[part 1 of 3: packages /MICROSAR/Dem_swc/DataTypes to /MICROSAR/Dem_swc/ComponentTypes]
AUTOSAR XML (schema 00053)
package /MICROSAR/Dem_swc/DataTypes
  27 x impl type:
    Dem_EventIdType: range raw 1..65535, implementation-data-type=uint16
    Dem_BufferLengthType: range raw 1..65535, implementation-data-type=uint16
    Dcm_NegativeResponseCodeType: range raw 1..255, implementation-data-type=uint8
    Dem_RatioIdType: range raw 1..65535, implementation-data-type=uint16
    Dem_DTCStatusMaskType: range raw 0..255, implementation-data-type=uint8
    Dem_OperationCycleIdType: range raw 0..255, implementation-data-type=uint8
    Dem_DTCGroupType: range raw 0..16777215, implementation-data-type=uint32
    Dem_MaxDataValueType: category=ARRAY, sw-calibration-access=READ-ONLY
      element Dem_MaxDataValueTypeElement: array-size=7, array-size-semantics=FIXED-SIZE, implementation-data-type=uint8
    Dem_EventStatusType:
      compu {0=DEM_EVENT_STATUS_PASSED, 1=DEM_EVENT_STATUS_FAILED, 2=DEM_EVENT_STATUS_PREPASSED, 3=DEM_EVENT_STATUS_PREFAILED, 4=DEM_EVENT_STATUS_FDC_THRESHOLD_REACHED, 5=DEM_EVENT_STATUS_PASSED_CONDITIONS_NOT_FULFILLED, 6=DEM_EVENT_STATUS_FAILED_CONDITIONS_NOT_FULFILLED, 7=DEM_EVENT_STATUS_PREPASSED_CONDITIONS_NOT_FULFILLED, 8=DEM_EVENT_STATUS_PREFAILED_CONDITIONS_NOT_FULFILLED}
      range raw 0..255
      implementation-data-type=uint8
    Dem_InitMonitorReasonType: compu {1=DEM_INIT_MONITOR_CLEAR, 2=DEM_INIT_MONITOR_RESTART, 3=DEM_INIT_MONITOR_REENABLED, 4=DEM_INIT_MONITOR_STORAGE_REENABLED}, range raw 1..4, implementation-data-type=uint8
    Dem_DTCOriginType: compu {1=DEM_DTC_ORIGIN_PRIMARY_MEMORY, 2=DEM_DTC_ORIGIN_MIRROR_MEMORY, 3=DEM_DTC_ORIGIN_PERMANENT_MEMORY, 4=DEM_DTC_ORIGIN_OBD_RELEVANT_MEMORY, 256=DEM_DTC_ORIGIN_SECONDARY_MEMORY}, range raw 1..511, implementation-data-type=uint16
    Dem_DTCFormatType: compu {0=DEM_DTC_FORMAT_OBD, 1=DEM_DTC_FORMAT_UDS, 2=DEM_DTC_FORMAT_J1939, 3=DEM_DTC_FORMAT_OBD_3BYTE}, range raw 0..3, implementation-data-type=uint8
    Dem_OperationCycleStateType: compu {0=DEM_CYCLE_STATE_START, 1=DEM_CYCLE_STATE_END}, range raw 0..1, implementation-data-type=uint8
    Dem_IndicatorStatusType: compu {0=DEM_INDICATOR_OFF, 1=DEM_INDICATOR_CONTINUOUS, 2=DEM_INDICATOR_BLINKING, 3=DEM_INDICATOR_BLINK_CONT, 4=DEM_INDICATOR_SLOW_FLASH, 5=DEM_INDICATOR_FAST_FLASH, 6=DEM_INDICATOR_ON_DEMAND, 7=DEM_INDICATOR_SHORT}, range raw 0..7, implementation-data-type=uint8
    Dem_DTCKindType: compu {1=DEM_DTC_KIND_ALL_DTCS, 2=DEM_DTC_KIND_EMISSION_REL_DTCS}, range raw 0..255, implementation-data-type=uint8
    Dem_IumprDenomCondIdType: compu {1=DEM_IUMPR_GENERAL_DENOMINATOR, 2=DEM_IUMPR_DEN_COND_COLDSTART, 3=DEM_IUMPR_DEN_COND_EVAP, 4=DEM_IUMPR_DEN_COND_500MI, 5=DEM_IUMPR_GENERAL_INDIVIDUAL_DENOMINATOR, 6=DEM_IUMPR_GENERAL_OBDCOND, 7=DEM_IUMPR_DEN_COND_INDEPENDENT}, range raw 0..255, implementation-data-type=uint8
    Dem_IumprDenomCondStatusType: compu {0=DEM_IUMPR_DEN_STATUS_NOT_REACHED, 1=DEM_IUMPR_DEN_STATUS_REACHED, 2=DEM_IUMPR_DEN_STATUS_INHIBITED}, range raw 0..255, implementation-data-type=uint8
    Dem_DebounceResetStatusType: compu {0=DEM_DEBOUNCE_STATUS_FREEZE, 1=DEM_DEBOUNCE_STATUS_RESET}, range raw 0..255, implementation-data-type=uint8
    Dem_IumprReadinessGroupType:
      compu {0=DEM_IUMPR_BOOSTPRS, 1=DEM_IUMPR_CAT1, 2=DEM_IUMPR_CAT2, 3=DEM_IUMPR_EGR, 4=DEM_IUMPR_EGSENSOR, 5=DEM_IUMPR_EVAP, 6=DEM_IUMPR_NMHCCAT, 7=DEM_IUMPR_NOXADSORB, 8=DEM_IUMPR_NOXCAT, 9=DEM_IUMPR_OXS1, 10=DEM_IUMPR_OXS2, 11=DEM_IUMPR_PMFILTER, 12=DEM_IUMPR_PRIVATE, 13=DEM_IUMPR_SAIR, 14=DEM_IUMPR_SECOXS1, 15=DEM_IUMPR_SECOXS2, 16=DEM_IUMPR_FLSYS, 17=DEM_IUMPR_AFRI1, 18=DEM_IUMPR_AFRI2, 19=DEM_IUMPR_PF1, 20=DEM_IUMPR_PF2, 255=DEM_IUMPR_ALLGROUPS}
      range raw 0..255
      implementation-data-type=uint8
    Dem_DTRControlType: compu {0=DEM_DTR_CTL_NORMAL, 1=DEM_DTR_CTL_NO_MAX, 2=DEM_DTR_CTL_NO_MIN, 3=DEM_DTR_CTL_RESET, 4=DEM_DTR_CTL_INVISIBLE}, range raw 0..255, implementation-data-type=uint8
    Dem_DebouncingStateType:
      compu {mask 1: 1=DEM_TEMPORARILY_DEFECTIVE (Bit 0: Temporarily Defective (corresponds to 0 < FDC < 127)), mask 2: 2=DEM_FINALLY_DEFECTIVE (Bit 1: Finally Defective (corresponds to FDC = 127)), mask 4: 4=DEM_TEMPORARILY_HEALED (Bit 2: Temporarily healed (corresponds to -128 < FDC < 0)), mask 8: 8=DEM_TEST_COMPLETE (Bit 3: Test complete (corresponds to FDC = -128 or FDC = 127)), mask 16: 16=DEM_DTR_UPDATE (Bit 4: DTR Update (= Test complete && Debouncing complete && enable conditions / storage conditions fulfilled))}
      range raw 0..255
      implementation-data-type=uint8
    Dem_DTCSeverityType:
      compu {mask 255: 0=DEM_SEVERITY_NO_SEVERITY (DTC_NO_SEVERITY) (No severity information available), mask 31: 1=DEM_SEVERITY_WWHOBD_CLASS_NO_CLASS (DTC_CLASS) (No class information), mask 31: 2=DEM_SEVERITY_WWHOBD_CLASS_A (DTC_CLASS) (WWH-OBD Class A), mask 31: 4=DEM_SEVERITY_WWHOBD_CLASS_B1 (DTC_CLASS) (WWH-OBD Class B1), mask 31: 8=DEM_SEVERITY_WWHOBD_CLASS_B2 (DTC_CLASS) (WWH-OBD Class B2), mask 31: 16=DEM_SEVERITY_WWHOBD_CLASS_C (DTC_CLASS) (WWH-OBD Class C), mask 224: 32=DEM_SEVERITY_MAINTENANCE_ONLY (DTC_SEVERITY) (Maintenance required), mask 224: 64=DEM_SEVERITY_CHECK_AT_NEXT_HALT (DTC_SEVERITY) (Check at next halt), mask 224: 128=DEM_SEVERITY_CHECK_IMMEDIATELY (DTC_SEVERITY) (Check immediately)}
      range raw 0..255
      implementation-data-type=uint8
    Dem_UdsStatusByteType:
      compu {mask 1: 1=DEM_UDS_STATUS_TF (bit 0: TestFailed), mask 2: 2=DEM_UDS_STATUS_TFTOC (bit 1: TestFailedThisOperationCycle), mask 4: 4=DEM_UDS_STATUS_PDTC (bit 2: PendingDTC), mask 8: 8=DEM_UDS_STATUS_CDTC (bit 3: ConfirmedDTC), mask 16: 16=DEM_UDS_STATUS_TNCSLC (bit 4: TestNotCompletedSinceLastClear), mask 32: 32=DEM_UDS_STATUS_TFSLC (bit 5: TestFailedSinceLastClear), mask 64: 64=DEM_UDS_STATUS_TNCTOC (bit 6: TestNotCompletedThisOperationCycle), mask 128: 128=DEM_UDS_STATUS_WIR (bit 7: WarningIndicatorRequested)}
      range raw 0..255
      implementation-data-type=uint8
    Dem_MonitorStatusType: compu {mask 1: 1=DEM_MONITOR_STATUS_TF (bit 0: TestFailed), mask 2: 2=DEM_MONITOR_STATUS_TNCTOC (bit 1: TestNotCompletedThisOperationCycle)}, range raw 0..255, implementation-data-type=uint8
    DataArrayType_uint8_1: category=ARRAY, sw-calibration-access=READ-ONLY
      element DataArrayType_uint8_1Element: array-size=1, array-size-semantics=FIXED-SIZE, implementation-data-type=uint8
    DataArrayType_uint8_2: category=ARRAY, sw-calibration-access=READ-ONLY
      element DataArrayType_uint8_2Element: array-size=2, array-size-semantics=FIXED-SIZE, implementation-data-type=uint8
    DataArrayType_uint8_7: category=ARRAY, sw-calibration-access=READ-ONLY
      element DataArrayType_uint8_7Element: array-size=7, array-size-semantics=FIXED-SIZE, implementation-data-type=uint8
package /MICROSAR/Dem_swc/Interfaces
  13 x client server interface, all with is-service=true, service-kind=DIAGNOSTIC-EVENT-MANAGER:
    DemServices
      operation GetPostRunRequested: possible-error=DemServices/E_NOT_OK
        arg IsRequested: type=boolean, direction=OUT
      operation GetDTCStatusAvailabilityMask: possible-error=DemServices/E_NOT_OK
        arg ClientId: type=uint8, direction=IN
        arg DTCStatusMask: type=uint8, direction=OUT
      operation SynchronizeNvData: possible-error=DemServices/E_NOT_OK
      error E_NOT_OK: error-code=1
    ClearDTC
      operation ClearDTC: possible-error=[ClearDTC/E_NOT_OK, DEM_CLEAR_FAILED, DEM_PENDING, DEM_CLEAR_BUSY, DEM_CLEAR_MEMORY_ERROR, DEM_WRONG_DTC, DEM_WRONG_DTCORIGIN]
      operation SelectDTC: possible-error=[ClearDTC/E_OK, ClearDTC/E_NOT_OK, DEM_BUSY]
        arg DTC: type=uint32, direction=IN
        arg DTCFormat: type=Dem_DTCFormatType, direction=IN
        arg DTCOrigin: type=Dem_DTCOriginType, direction=IN
      9 x error:
        E_OK: error-code=0
        E_NOT_OK: error-code=1
        DEM_CLEAR_FAILED: error-code=7
        DEM_PENDING: error-code=4
        DEM_CLEAR_BUSY: error-code=5
        DEM_BUSY: error-code=22
        DEM_CLEAR_MEMORY_ERROR: error-code=6
        DEM_WRONG_DTC: error-code=8
        DEM_WRONG_DTCORIGIN: error-code=9
    EvMemOverflowIndication
      operation GetEventMemoryOverflow: possible-error=EvMemOverflowIndication/E_NOT_OK
        arg OverflowIndication: type=boolean, direction=OUT
      operation GetNumberOfEventMemoryEntries: possible-error=EvMemOverflowIndication/E_NOT_OK
        arg NumberOfEventMemoryEntries: type=uint8, direction=OUT
      error E_NOT_OK: error-code=1
    GeneralDiagnosticInfo
      11 x operation:
        GetEventUdsStatus: possible-error=GeneralDiagnosticInfo/E_NOT_OK
          arg EventId: type=Dem_EventIdType, direction=IN
          arg UDSStatusByte: type=Dem_UdsStatusByteType, direction=OUT
        GetEventStatus: possible-error=GeneralDiagnosticInfo/E_NOT_OK
          arg EventId: type=Dem_EventIdType, direction=IN
          arg UDSStatusByte: type=Dem_UdsStatusByteType, direction=OUT
        GetEventFailed: possible-error=GeneralDiagnosticInfo/E_NOT_OK
          arg EventId: type=Dem_EventIdType, direction=IN
          arg EventFailed: type=boolean, direction=OUT
        GetEventTested: possible-error=GeneralDiagnosticInfo/E_NOT_OK
          arg EventId: type=Dem_EventIdType, direction=IN
          arg EventTested: type=boolean, direction=OUT
        GetDTCOfEvent: possible-error=[GeneralDiagnosticInfo/E_NOT_OK, GeneralDiagnosticInfo/DEM_E_NO_DTC_AVAILABLE]
          arg EventId: type=Dem_EventIdType, direction=IN
          arg DTCFormat: type=Dem_DTCFormatType, direction=IN
          arg DTCOfEvent: type=uint32, direction=OUT
        GetFaultDetectionCounter: possible-error=[GeneralDiagnosticInfo/E_NOT_OK, GeneralDiagnosticInfo/DEM_E_NO_FDC_AVAILABLE]
          arg EventId: type=Dem_EventIdType, direction=IN
          arg FaultDetectionCounter: type=sint8, direction=OUT
        GetEventFreezeFrameDataEx: possible-error=[GeneralDiagnosticInfo/E_NOT_OK, GeneralDiagnosticInfo/DEM_BUFFER_TOO_SMALL, GeneralDiagnosticInfo/DEM_NO_SUCH_ELEMENT]
          5 x arg:
            EventId: type=Dem_EventIdType, direction=IN
            RecordNumber: type=uint8, direction=IN
            DataId: type=uint16, direction=IN
            DestBuffer: type=Dem_MaxDataValueType, direction=OUT
            BufSize: type=uint16, direction=INOUT
        GetEventExtendedDataRecordEx: possible-error=[GeneralDiagnosticInfo/E_NOT_OK, GeneralDiagnosticInfo/DEM_BUFFER_TOO_SMALL, GeneralDiagnosticInfo/DEM_NO_SUCH_ELEMENT]
          4 x arg:
            EventId: type=Dem_EventIdType, direction=IN
            RecordNumber: type=uint8, direction=IN
            DestBuffer: type=Dem_MaxDataValueType, direction=OUT
            BufSize: type=uint16, direction=INOUT
        GetEventEnableCondition: possible-error=GeneralDiagnosticInfo/E_NOT_OK
          arg EventId: type=Dem_EventIdType, direction=IN
          arg ConditionFullfilled: type=boolean, direction=OUT
        GetDebouncingOfEvent: possible-error=GeneralDiagnosticInfo/E_NOT_OK
          arg EventId: type=Dem_EventIdType, direction=IN
          arg DebouncingState: type=Dem_DebouncingStateType, direction=OUT
        GetMonitorStatus: possible-error=GeneralDiagnosticInfo/E_NOT_OK
          arg EventId: type=Dem_EventIdType, direction=IN
          arg MonitorStatus: type=Dem_MonitorStatusType, direction=OUT
      5 x error:
        E_NOT_OK: error-code=1
        DEM_E_NO_DTC_AVAILABLE: error-code=10
        DEM_E_NO_FDC_AVAILABLE: error-code=14
        DEM_BUFFER_TOO_SMALL: error-code=21
        DEM_NO_SUCH_ELEMENT: error-code=48
    OperationCycle
      operation GetOperationCycleState: possible-error=[OperationCycle/E_OK, OperationCycle/E_NOT_OK]
        arg CycleState: type=Dem_OperationCycleStateType, direction=OUT
      operation SetOperationCycleState: possible-error=[OperationCycle/E_OK, OperationCycle/E_NOT_OK]
        arg CycleState: type=Dem_OperationCycleStateType, direction=IN
      error E_OK: error-code=0
      error E_NOT_OK: error-code=1
    CSDataServices_Data_DID_0x1117_Sensor_Availability_Flag_Information
      operation ReadData: possible-error=CSDataServices_Data_DID_0x1117_Sensor_Availability_Flag_Information/E_NOT_OK
        arg Data: type=DataArrayType_uint8_1, direction=OUT
      error E_NOT_OK: error-code=1
    CSDataServices_Data_DID_0xa004_Ego_Acceleration
      operation ReadData: possible-error=CSDataServices_Data_DID_0xa004_Ego_Acceleration/E_NOT_OK
        arg Data: type=DataArrayType_uint8_1, direction=OUT
      error E_NOT_OK: error-code=1
    CSDataServices_Data_DID_0x1111_ECUVoltage
      operation ReadData: possible-error=CSDataServices_Data_DID_0x1111_ECUVoltage/E_NOT_OK
        arg Data: type=DataArrayType_uint8_2, direction=OUT
      error E_NOT_OK: error-code=1
    CSDataServices_Data_DID_0x1116_CombinedSignal
      operation ReadData: possible-error=CSDataServices_Data_DID_0x1116_CombinedSignal/E_NOT_OK
        arg Data: type=DataArrayType_uint8_7, direction=OUT
      error E_NOT_OK: error-code=1
    DiagnosticInfo
      11 x operation:
        GetEventUdsStatus: possible-error=DiagnosticInfo/E_NOT_OK
          arg UDSStatusByte: type=Dem_UdsStatusByteType, direction=OUT
        GetEventStatus: possible-error=DiagnosticInfo/E_NOT_OK
          arg UDSStatusByte: type=Dem_UdsStatusByteType, direction=OUT
        GetEventFailed: possible-error=DiagnosticInfo/E_NOT_OK
          arg EventFailed: type=boolean, direction=OUT
        GetEventTested: possible-error=DiagnosticInfo/E_NOT_OK
          arg EventTested: type=boolean, direction=OUT
        GetDTCOfEvent: possible-error=[DiagnosticInfo/E_NOT_OK, DiagnosticInfo/DEM_E_NO_DTC_AVAILABLE]
          arg DTCFormat: type=Dem_DTCFormatType, direction=IN
          arg DTCOfEvent: type=uint32, direction=OUT
        GetFaultDetectionCounter: possible-error=[DiagnosticInfo/E_NOT_OK, DiagnosticInfo/DEM_E_NO_FDC_AVAILABLE]
          arg FaultDetectionCounter: type=sint8, direction=OUT
        GetEventFreezeFrameDataEx: possible-error=[DiagnosticInfo/E_NOT_OK, DiagnosticInfo/DEM_BUFFER_TOO_SMALL, DiagnosticInfo/DEM_NO_SUCH_ELEMENT]
          4 x arg:
            RecordNumber: type=uint8, direction=IN
            DataId: type=uint16, direction=IN
            DestBuffer: type=Dem_MaxDataValueType, direction=OUT
            BufSize: type=uint16, direction=INOUT
        GetEventExtendedDataRecordEx: possible-error=[DiagnosticInfo/E_NOT_OK, DiagnosticInfo/DEM_BUFFER_TOO_SMALL, DiagnosticInfo/DEM_NO_SUCH_ELEMENT]
          arg RecordNumber: type=uint8, direction=IN
          arg DestBuffer: type=Dem_MaxDataValueType, direction=OUT
          arg BufSize: type=uint16, direction=INOUT
        GetEventEnableCondition: possible-error=DiagnosticInfo/E_NOT_OK
          arg ConditionFullfilled: type=boolean, direction=OUT
        GetDebouncingOfEvent: possible-error=DiagnosticInfo/E_NOT_OK
          arg DebouncingState: type=Dem_DebouncingStateType, direction=OUT
        GetMonitorStatus: possible-error=DiagnosticInfo/E_NOT_OK
          arg MonitorStatus: type=Dem_MonitorStatusType, direction=OUT
      5 x error:
        E_NOT_OK: error-code=1
        DEM_E_NO_DTC_AVAILABLE: error-code=10
        DEM_E_NO_FDC_AVAILABLE: error-code=14
        DEM_BUFFER_TOO_SMALL: error-code=21
        DEM_NO_SUCH_ELEMENT: error-code=48
    DiagnosticMonitor
      11 x operation:
        SetEventStatus: possible-error=DiagnosticMonitor/E_NOT_OK
          arg EventStatus: type=Dem_EventStatusType, direction=IN
        ResetEventStatus: possible-error=DiagnosticMonitor/E_NOT_OK
        ResetEventDebounceStatus: possible-error=DiagnosticMonitor/E_NOT_OK
          arg DebounceResetStatus: type=Dem_DebounceResetStatusType, direction=IN
        GetEventUdsStatus: possible-error=DiagnosticMonitor/E_NOT_OK
          arg UDSStatusByte: type=Dem_UdsStatusByteType, direction=OUT
        GetEventStatus: possible-error=DiagnosticMonitor/E_NOT_OK
          arg UDSStatusByte: type=Dem_UdsStatusByteType, direction=OUT
        GetEventFailed: possible-error=DiagnosticMonitor/E_NOT_OK
          arg EventFailed: type=boolean, direction=OUT
        GetEventTested: possible-error=DiagnosticMonitor/E_NOT_OK
          arg EventTested: type=boolean, direction=OUT
        GetDTCOfEvent: possible-error=[DiagnosticMonitor/E_NOT_OK, DiagnosticMonitor/DEM_E_NO_DTC_AVAILABLE]
          arg DTCFormat: type=Dem_DTCFormatType, direction=IN
          arg DTCOfEvent: type=uint32, direction=OUT
        GetFaultDetectionCounter: possible-error=[DiagnosticMonitor/E_NOT_OK, DiagnosticMonitor/DEM_E_NO_FDC_AVAILABLE]
          arg FaultDetectionCounter: type=sint8, direction=OUT
        GetEventFreezeFrameDataEx: possible-error=[DiagnosticMonitor/E_NOT_OK, DiagnosticMonitor/DEM_BUFFER_TOO_SMALL, DiagnosticMonitor/DEM_NO_SUCH_ELEMENT]
          4 x arg:
            RecordNumber: type=uint8, direction=IN
            DataId: type=uint16, direction=IN
            DestBuffer: type=Dem_MaxDataValueType, direction=OUT
            BufSize: type=uint16, direction=INOUT
        GetEventExtendedDataRecordEx: possible-error=[DiagnosticMonitor/E_NOT_OK, DiagnosticMonitor/DEM_BUFFER_TOO_SMALL, DiagnosticMonitor/DEM_NO_SUCH_ELEMENT]
          arg RecordNumber: type=uint8, direction=IN
          arg DestBuffer: type=Dem_MaxDataValueType, direction=OUT
          arg BufSize: type=uint16, direction=INOUT
      5 x error:
        E_NOT_OK: error-code=1
        DEM_E_NO_DTC_AVAILABLE: error-code=10
        DEM_E_NO_FDC_AVAILABLE: error-code=14
        DEM_BUFFER_TOO_SMALL: error-code=21
        DEM_NO_SUCH_ELEMENT: error-code=48
    CSDataServices_Data_DID_0x1112_VehicleSpeed
      operation ReadData: possible-error=CSDataServices_Data_DID_0x1112_VehicleSpeed/E_NOT_OK
        arg Data: type=DataArrayType_uint8_2, direction=OUT
      error E_NOT_OK: error-code=1
    CallbackDTCStatusChange
      operation DTCStatusChanged: possible-error=CallbackDTCStatusChange/E_NOT_OK
        arg DTC: type=uint32, direction=IN
        arg DTCStatusOld: type=Dem_UdsStatusByteType, direction=IN
        arg DTCStatusNew: type=Dem_UdsStatusByteType, direction=IN
      error E_NOT_OK: error-code=1
package /MICROSAR/Dem_swc/ComponentTypes
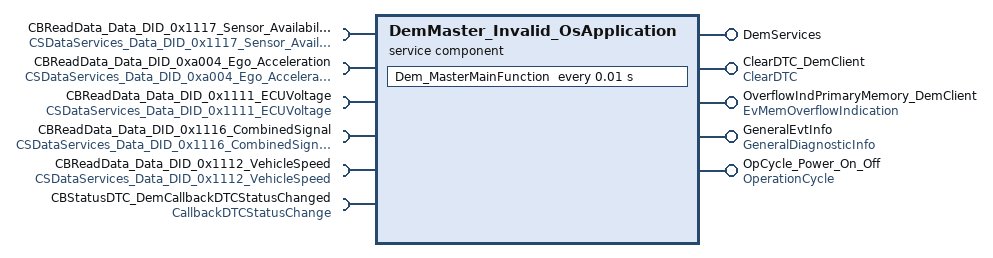
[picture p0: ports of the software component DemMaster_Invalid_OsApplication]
  service sw component type DemMaster_Invalid_OsApplication: category=SERVICE_COMPONENT
    5 x provide port:
      DemServices: provided-interface=DemServices
      ClearDTC_DemClient: provided-interface=ClearDTC
      OverflowIndPrimaryMemory_DemClient: provided-interface=EvMemOverflowIndication
      GeneralEvtInfo: provided-interface=GeneralDiagnosticInfo
      OpCycle_Power_On_Off: provided-interface=OperationCycle
    6 x require port:
      CBReadData_Data_DID_0x1117_Sensor_Availability_Flag_Information: required-interface=CSDataServices_Data_DID_0x1117_Sensor_Availability_Flag_Information
      CBReadData_Data_DID_0xa004_Ego_Acceleration: required-interface=CSDataServices_Data_DID_0xa004_Ego_Acceleration
      CBReadData_Data_DID_0x1111_ECUVoltage: required-interface=CSDataServices_Data_DID_0x1111_ECUVoltage
      CBReadData_Data_DID_0x1116_CombinedSignal: required-interface=CSDataServices_Data_DID_0x1116_CombinedSignal
      CBReadData_Data_DID_0x1112_VehicleSpeed: required-interface=CSDataServices_Data_DID_0x1112_VehicleSpeed
      CBStatusDTC_DemCallbackDTCStatusChanged: required-interface=CallbackDTCStatusChange
    behavior DemMaster_Invalid_OsApplicationInternalBehavior: handle-termination-and-restart=NO-SUPPORT, included-data-type-set=data-type=[Dem_EventIdType, Dem_BufferLengthType, Dcm_NegativeResponseCodeType, Dem_RatioIdType, Dem_EventStatusType, Dem_UdsStatusByteType, Dem_DTCFormatType, Dem_InitMonitorReasonType, Dem_OperationCycleStateType, Dem_DTCStatusMaskType, Dem_IndicatorStatusType, Dem_MaxDataValueType, Dem_DTCKindType, Dem_DTCGroupType, Dem_IumprDenomCondIdType, Dem_IumprDenomCondStatusType, Dem_DebounceResetStatusType, Dem_DebouncingStateType, Dem_IumprReadinessGroupType, Dem_DTRControlType, Dem_DTCSeverityType, Dem_MonitorStatusType]
      timing event Timer_Dem_MasterMainFunction: start-on-event=Dem_MasterMainFunction, period=0.01
      20 x operation invoked event:
        OpEventPostRunRequested_GetPostRunRequested_DemServices: start-on-event=PostRunRequested, operation=DemServices.GetPostRunRequested
        OpEventGetDTCStatusAvailabilityMask_GetDTCStatusAvailabilityMask_DemServices: start-on-event=GetDTCStatusAvailabilityMask, operation=DemServices.GetDTCStatusAvailabilityMask
        OpEventClearDTC_ClearDTC_ClearDTC_DemClient: start-on-event=ClearDTC, operation=ClearDTC_DemClient.ClearDTC
        OpEventSelectDTC_SelectDTC_ClearDTC_DemClient: start-on-event=SelectDTC, operation=ClearDTC_DemClient.SelectDTC
        OpEventGetEventMemoryOverflow_GetEventMemoryOverflow_OverflowIndPrimaryMemory_DemClient: start-on-event=GetEventMemoryOverflow, operation=OverflowIndPrimaryMemory_DemClient.GetEventMemoryOverflow
        OpEventGetNumberOfEventMemoryEntries_GetNumberOfEventMemoryEntries_OverflowIndPrimaryMemory_DemClient: start-on-event=GetNumberOfEventMemoryEntries, operation=OverflowIndPrimaryMemory_DemClient.GetNumberOfEventMemoryEntries
        OpEventGetEventUdsStatus_GetEventUdsStatus_GeneralEvtInfo: start-on-event=DemMaster_Invalid_OsApplicationInternalBehavior/GetEventUdsStatus, operation=GeneralEvtInfo.GetEventUdsStatus
        OpEventGetEventStatus_GetEventStatus_GeneralEvtInfo: start-on-event=DemMaster_Invalid_OsApplicationInternalBehavior/GetEventStatus, operation=GeneralEvtInfo.GetEventStatus
        OpEventGetEventFailed_GetEventFailed_GeneralEvtInfo: start-on-event=DemMaster_Invalid_OsApplicationInternalBehavior/GetEventFailed, operation=GeneralEvtInfo.GetEventFailed
        OpEventGetEventTested_GetEventTested_GeneralEvtInfo: start-on-event=DemMaster_Invalid_OsApplicationInternalBehavior/GetEventTested, operation=GeneralEvtInfo.GetEventTested
        OpEventGetDTCOfEvent_GetDTCOfEvent_GeneralEvtInfo: start-on-event=DemMaster_Invalid_OsApplicationInternalBehavior/GetDTCOfEvent, operation=GeneralEvtInfo.GetDTCOfEvent
        OpEventGetFaultDetectionCounter_GetFaultDetectionCounter_GeneralEvtInfo: start-on-event=DemMaster_Invalid_OsApplicationInternalBehavior/GetFaultDetectionCounter, operation=GeneralEvtInfo.GetFaultDetectionCounter
        OpEventGetEventFreezeFrameDataEx_GetEventFreezeFrameDataEx_GeneralEvtInfo: start-on-event=DemMaster_Invalid_OsApplicationInternalBehavior/GetEventFreezeFrameDataEx, operation=GeneralEvtInfo.GetEventFreezeFrameDataEx
        OpEventGetEventExtendedDataRecordEx_GetEventExtendedDataRecordEx_GeneralEvtInfo: start-on-event=DemMaster_Invalid_OsApplicationInternalBehavior/GetEventExtendedDataRecordEx, operation=GeneralEvtInfo.GetEventExtendedDataRecordEx
        OpEventGetEventEnableCondition_GetEventEnableCondition_GeneralEvtInfo: start-on-event=DemMaster_Invalid_OsApplicationInternalBehavior/GetEventEnableCondition, operation=GeneralEvtInfo.GetEventEnableCondition
        OpEventGetDebouncingOfEvent_GetDebouncingOfEvent_GeneralEvtInfo: start-on-event=DemMaster_Invalid_OsApplicationInternalBehavior/GetDebouncingOfEvent, operation=GeneralEvtInfo.GetDebouncingOfEvent
        OpEventGetMonitorStatus_GetMonitorStatus_GeneralEvtInfo: start-on-event=DemMaster_Invalid_OsApplicationInternalBehavior/GetMonitorStatus, operation=GeneralEvtInfo.GetMonitorStatus
        OpEventGetOperationCycleState_GetOperationCycleState_OpCycle_Power_On_Off: start-on-event=GetOperationCycleState, operation=OpCycle_Power_On_Off.GetOperationCycleState
        OpEventSetOperationCycleState_SetOperationCycleState_OpCycle_Power_On_Off: start-on-event=SetOperationCycleState, operation=OpCycle_Power_On_Off.SetOperationCycleState
        OpEventSynchronizeNvData_SynchronizeNvData_DemServices: start-on-event=SynchronizeNvData, operation=DemServices.SynchronizeNvData
      port-api-options:
        enable-take-address=true, indirect-api=false, port=DemServices
        {enable-take-address=true, indirect-api=false, port-defined-argument-value{value=0, value-type=uint8}, port=ClearDTC_DemClient}
        {enable-take-address=true, indirect-api=false, port-arg-values=[{value=0, value-type=uint8}, {value=1, value-type=Dem_DTCOriginType}], port=OverflowIndPrimaryMemory_DemClient}
        enable-take-address=true, indirect-api=false, port=DemMaster_Invalid_OsApplication/GeneralEvtInfo
        enable-take-address=true, indirect-api=false, port=CBReadData_Data_DID_0x1117_Sensor_Availability_Flag_Information
        enable-take-address=true, indirect-api=false, port=CBReadData_Data_DID_0xa004_Ego_Acceleration
        enable-take-address=true, indirect-api=false, port=CBReadData_Data_DID_0x1111_ECUVoltage
        enable-take-address=true, indirect-api=false, port=CBReadData_Data_DID_0x1116_CombinedSignal
        enable-take-address=true, indirect-api=false, port=CBReadData_Data_DID_0x1112_VehicleSpeed
        {enable-take-address=true, indirect-api=false, port-defined-argument-value{value=0, value-type=uint8}, port=OpCycle_Power_On_Off}
        enable-take-address=true, indirect-api=false, port=CBStatusDTC_DemCallbackDTCStatusChanged
      21 x runnable:
        Dem_MasterMainFunction
          6 x sync call, all with timeout=0:
            OpServerCallDem_MasterMainFunction_ReadData_CBReadData_Data_DID_0x1117_Sensor_Availability_Flag_Information: operation=CBReadData_Data_DID_0x1117_Sensor_Availability_Flag_Information.ReadData
            OpServerCallDem_MasterMainFunction_ReadData_CBReadData_Data_DID_0xa004_Ego_Acceleration: operation=CBReadData_Data_DID_0xa004_Ego_Acceleration.ReadData
            OpServerCallDem_MasterMainFunction_ReadData_CBReadData_Data_DID_0x1111_ECUVoltage: operation=CBReadData_Data_DID_0x1111_ECUVoltage.ReadData
            OpServerCallDem_MasterMainFunction_ReadData_CBReadData_Data_DID_0x1116_CombinedSignal: operation=CBReadData_Data_DID_0x1116_CombinedSignal.ReadData
            OpServerCallDem_MasterMainFunction_ReadData_CBReadData_Data_DID_0x1112_VehicleSpeed: operation=CBReadData_Data_DID_0x1112_VehicleSpeed.ReadData
            OpServerCallDem_MasterMainFunction_DTCStatusChanged_CBStatusDTC_DemCallbackDTCStatusChanged: operation=CBStatusDTC_DemCallbackDTCStatusChanged.DTCStatusChanged
        PostRunRequested: can-be-invoked-concurrently=true, symbol=Dem_PostRunRequested
        GetDTCStatusAvailabilityMask: can-be-invoked-concurrently=true, symbol=Dem_GetDTCStatusAvailabilityMask
        ClearDTC: can-be-invoked-concurrently=true, symbol=Dem_ClearDTC
        SelectDTC: can-be-invoked-concurrently=true, symbol=Dem_SelectDTC
        GetEventMemoryOverflow: can-be-invoked-concurrently=true, symbol=Dem_GetEventMemoryOverflow
        GetNumberOfEventMemoryEntries: can-be-invoked-concurrently=true, symbol=Dem_GetNumberOfEventMemoryEntries
        GetEventUdsStatus: can-be-invoked-concurrently=true, symbol=Dem_GetEventUdsStatus
        GetEventStatus: can-be-invoked-concurrently=true, symbol=Dem_GetEventUdsStatus
        GetEventFailed: can-be-invoked-concurrently=true, symbol=Dem_GetEventFailed
        GetEventTested: can-be-invoked-concurrently=true, symbol=Dem_GetEventTested
        GetDTCOfEvent: can-be-invoked-concurrently=true, symbol=Dem_GetDTCOfEvent
        GetFaultDetectionCounter: can-be-invoked-concurrently=true, symbol=Dem_GetFaultDetectionCounter
        GetEventFreezeFrameDataEx: can-be-invoked-concurrently=true, symbol=Dem_GetEventFreezeFrameDataEx
        GetEventExtendedDataRecordEx: can-be-invoked-concurrently=true, symbol=Dem_GetEventExtendedDataRecordEx
        GetEventEnableCondition: can-be-invoked-concurrently=true, symbol=Dem_GetEventEnableCondition
        GetDebouncingOfEvent: can-be-invoked-concurrently=true, symbol=Dem_GetDebouncingOfEvent
        GetMonitorStatus: can-be-invoked-concurrently=true, symbol=Dem_GetMonitorStatus
        GetOperationCycleState: can-be-invoked-concurrently=true, symbol=Dem_GetOperationCycleState
        SetOperationCycleState: can-be-invoked-concurrently=true, symbol=Dem_SetOperationCycleState
        SynchronizeNvData: can-be-invoked-concurrently=true, symbol=Dem_RequestNvSynchronization
  swc implementation DemMaster_Invalid_OsApplicationImplementation: programming-language=C, behavior=DemMaster_Invalid_OsApplicationInternalBehavior
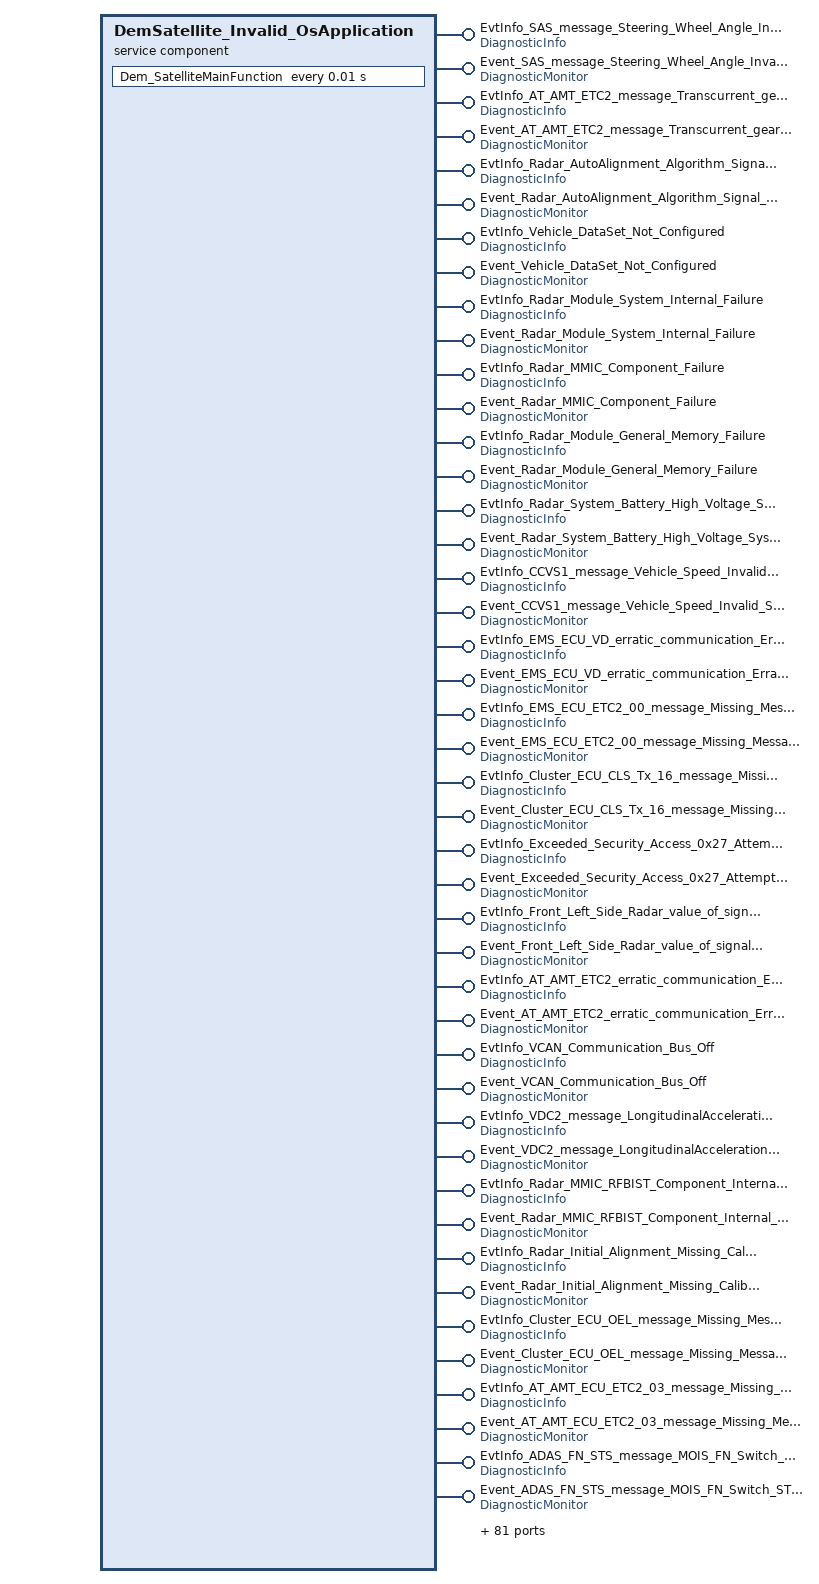
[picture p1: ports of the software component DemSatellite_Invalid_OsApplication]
  service sw component type DemSatellite_Invalid_OsApplication: category=SERVICE_COMPONENT
    125 x provide port:
      EvtInfo_SAS_message_Steering_Wheel_Angle_Invalid_Serial_Data_Received: provided-interface=DiagnosticInfo
      Event_SAS_message_Steering_Wheel_Angle_Invalid_Serial_Data_Received: provided-interface=DiagnosticMonitor
      EvtInfo_AT_AMT_ETC2_message_Transcurrent_gear_Invalid_Serial_Data_Received: provided-interface=DiagnosticInfo
      Event_AT_AMT_ETC2_message_Transcurrent_gear_Invalid_Serial_Data_Received: provided-interface=DiagnosticMonitor
      EvtInfo_Radar_AutoAlignment_Algorithm_Signal_Calculation_Failure: provided-interface=DiagnosticInfo
      Event_Radar_AutoAlignment_Algorithm_Signal_Calculation_Failure: provided-interface=DiagnosticMonitor
      EvtInfo_Vehicle_DataSet_Not_Configured: provided-interface=DiagnosticInfo
      Event_Vehicle_DataSet_Not_Configured: provided-interface=DiagnosticMonitor
      EvtInfo_Radar_Module_System_Internal_Failure: provided-interface=DiagnosticInfo
      Event_Radar_Module_System_Internal_Failure: provided-interface=DiagnosticMonitor
      EvtInfo_Radar_MMIC_Component_Failure: provided-interface=DiagnosticInfo
      Event_Radar_MMIC_Component_Failure: provided-interface=DiagnosticMonitor
      EvtInfo_Radar_Module_General_Memory_Failure: provided-interface=DiagnosticInfo
      Event_Radar_Module_General_Memory_Failure: provided-interface=DiagnosticMonitor
      EvtInfo_Radar_System_Battery_High_Voltage_System_Voltage_High: provided-interface=DiagnosticInfo
      Event_Radar_System_Battery_High_Voltage_System_Voltage_High: provided-interface=DiagnosticMonitor
      EvtInfo_CCVS1_message_Vehicle_Speed_Invalid_Serial_Data_Received: provided-interface=DiagnosticInfo
      Event_CCVS1_message_Vehicle_Speed_Invalid_Serial_Data_Received: provided-interface=DiagnosticMonitor
      EvtInfo_EMS_ECU_VD_erratic_communication_Erratic: provided-interface=DiagnosticInfo
      Event_EMS_ECU_VD_erratic_communication_Erratic: provided-interface=DiagnosticMonitor
      EvtInfo_EMS_ECU_ETC2_00_message_Missing_Message: provided-interface=DiagnosticInfo
      Event_EMS_ECU_ETC2_00_message_Missing_Message: provided-interface=DiagnosticMonitor
      EvtInfo_Cluster_ECU_CLS_Tx_16_message_Missing_Message: provided-interface=DiagnosticInfo
      Event_Cluster_ECU_CLS_Tx_16_message_Missing_Message: provided-interface=DiagnosticMonitor
      EvtInfo_Exceeded_Security_Access_0x27_Attempt_Threshold_Authentication_Failure: provided-interface=DiagnosticInfo
      Event_Exceeded_Security_Access_0x27_Attempt_Threshold_Authentication_Failure: provided-interface=DiagnosticMonitor
      EvtInfo_Front_Left_Side_Radar_value_of_signal_protection_calculation_Incorrect: provided-interface=DiagnosticInfo
      Event_Front_Left_Side_Radar_value_of_signal_protection_calculation_Incorrect: provided-interface=DiagnosticMonitor
      EvtInfo_AT_AMT_ETC2_erratic_communication_Erratic: provided-interface=DiagnosticInfo
      Event_AT_AMT_ETC2_erratic_communication_Erratic: provided-interface=DiagnosticMonitor
      EvtInfo_VCAN_Communication_Bus_Off: provided-interface=DiagnosticInfo
      Event_VCAN_Communication_Bus_Off: provided-interface=DiagnosticMonitor
      EvtInfo_VDC2_message_LongitudinalAcceleration_Invalid_Serial_Data_Received: provided-interface=DiagnosticInfo
      Event_VDC2_message_LongitudinalAcceleration_Invalid_Serial_Data_Received: provided-interface=DiagnosticMonitor
      EvtInfo_Radar_MMIC_RFBIST_Component_Internal_Failure: provided-interface=DiagnosticInfo
      Event_Radar_MMIC_RFBIST_Component_Internal_Failure: provided-interface=DiagnosticMonitor
      EvtInfo_Radar_Initial_Alignment_Missing_Calibration: provided-interface=DiagnosticInfo
      Event_Radar_Initial_Alignment_Missing_Calibration: provided-interface=DiagnosticMonitor
      EvtInfo_Cluster_ECU_OEL_message_Missing_Message: provided-interface=DiagnosticInfo
      Event_Cluster_ECU_OEL_message_Missing_Message: provided-interface=DiagnosticMonitor
      EvtInfo_AT_AMT_ECU_ETC2_03_message_Missing_Message: provided-interface=DiagnosticInfo
      Event_AT_AMT_ECU_ETC2_03_message_Missing_Message: provided-interface=DiagnosticMonitor
      EvtInfo_ADAS_FN_STS_message_MOIS_FN_Switch_STS_Invalid_Serial_Data_Received: provided-interface=DiagnosticInfo
      Event_ADAS_FN_STS_message_MOIS_FN_Switch_STS_Invalid_Serial_Data_Received: provided-interface=DiagnosticMonitor
      EvtInfo_Radar_Module_Over_Temperature: provided-interface=DiagnosticInfo
      Event_Radar_Module_Over_Temperature: provided-interface=DiagnosticMonitor
      EvtInfo_PCAN_TimeSync_Missing_Message: provided-interface=DiagnosticInfo
      Event_PCAN_TimeSync_Missing_Message: provided-interface=DiagnosticMonitor
      EvtInfo_Radar_Module_Watchdog_Failure: provided-interface=DiagnosticInfo
      Event_Radar_Module_Watchdog_Failure: provided-interface=DiagnosticMonitor
      EvtInfo_SAS_ECU_SAS_message_Missing_Message: provided-interface=DiagnosticInfo
      Event_SAS_ECU_SAS_message_Missing_Message: provided-interface=DiagnosticMonitor
      EvtInfo_ECU_NVM_Corruption_Program_memory_Failure: provided-interface=DiagnosticInfo
      Event_ECU_NVM_Corruption_Program_memory_Failure: provided-interface=DiagnosticMonitor
      EvtInfo_Cluster_ECU_TD_message_Missing_Message: provided-interface=DiagnosticInfo
      Event_Cluster_ECU_TD_message_Missing_Message: provided-interface=DiagnosticMonitor
      EvtInfo_PCAN_Communication_Bus_Off: provided-interface=DiagnosticInfo
      Event_PCAN_Communication_Bus_Off: provided-interface=DiagnosticMonitor
      EvtInfo_Front_Left_Side_Radar_Missing_Message: provided-interface=DiagnosticInfo
      Event_Front_Left_Side_Radar_Missing_Message: provided-interface=DiagnosticMonitor
      EvtInfo_Manual_ETC2_message_Transcurrent_gear_Invalid_Serial_Data_Received: provided-interface=DiagnosticInfo
      Event_Manual_ETC2_message_Transcurrent_gear_Invalid_Serial_Data_Received: provided-interface=DiagnosticMonitor
      EvtInfo_SAS_ECU_erratic_communication_Erratic: provided-interface=DiagnosticInfo
      Event_SAS_ECU_erratic_communication_Erratic: provided-interface=DiagnosticMonitor
      EvtInfo_VDC2_message_Yaw_rate_Invalid_Serial_Data_Received: provided-interface=DiagnosticInfo
      Event_VDC2_message_Yaw_rate_Invalid_Serial_Data_Received: provided-interface=DiagnosticMonitor
      EvtInfo_Cluster_ECU_TD_erratic_communication_Erratic: provided-interface=DiagnosticInfo
      Event_Cluster_ECU_TD_erratic_communication_Erratic: provided-interface=DiagnosticMonitor
      EvtInfo_EMS_ECU_CCVS1_message_Missing_Message: provided-interface=DiagnosticInfo
      Event_EMS_ECU_CCVS1_message_Missing_Message: provided-interface=DiagnosticMonitor
      EvtInfo_Radar_Mounting_Orientation_Incorrect_Assembly: provided-interface=DiagnosticInfo
      Event_Radar_Mounting_Orientation_Incorrect_Assembly: provided-interface=DiagnosticMonitor
      EvtInfo_EMS_ECU_ETC2_erratic_communication_Erractic: provided-interface=DiagnosticInfo
      Event_EMS_ECU_ETC2_erratic_communication_Erractic: provided-interface=DiagnosticMonitor
      EvtInfo_Cluster_ECU_ADAS_FN_STS_erratic_communication_Erratic: provided-interface=DiagnosticInfo
      Event_Cluster_ECU_ADAS_FN_STS_erratic_communication_Erratic: provided-interface=DiagnosticMonitor
      EvtInfo_ESC_ECU_VDC2_message_Missing_Message: provided-interface=DiagnosticInfo
      Event_ESC_ECU_VDC2_message_Missing_Message: provided-interface=DiagnosticMonitor
      EvtInfo_CLS_TX_16_message_Transmission_Type_info_Invalid_Serial_Data_Received: provided-interface=DiagnosticInfo
      Event_CLS_TX_16_message_Transmission_Type_info_Invalid_Serial_Data_Received: provided-interface=DiagnosticMonitor
      EvtInfo_Cluster_ECU_CLS_Tx_4_erratic_communication_Erratic: provided-interface=DiagnosticInfo
      Event_Cluster_ECU_CLS_Tx_4_erratic_communication_Erratic: provided-interface=DiagnosticMonitor
      EvtInfo_Cluster_ECU_ADAS_FN_STS_message_Missing_Message: provided-interface=DiagnosticInfo
      Event_Cluster_ECU_ADAS_FN_STS_message_Missing_Message: provided-interface=DiagnosticMonitor
      EvtInfo_Vehicle_Dataset_value_of_signal_protection_calculation_Incorrect: provided-interface=DiagnosticInfo
      Event_Vehicle_Dataset_value_of_signal_protection_calculation_Incorrect: provided-interface=DiagnosticMonitor
      EvtInfo_Cluster_ECU_CLS_Tx_16_erratic_communication_Erratic: provided-interface=DiagnosticInfo
      Event_Cluster_ECU_CLS_Tx_16_erratic_communication_Erratic: provided-interface=DiagnosticMonitor
      EvtInfo_Cluster_ECU_OEL_erratic_communication_Erratic: provided-interface=DiagnosticInfo
      Event_Cluster_ECU_OEL_erratic_communication_Erratic: provided-interface=DiagnosticMonitor
      EvtInfo_Cluster_ECU_CLS_Tx_4_message_Missing_Message: provided-interface=DiagnosticInfo
      Event_Cluster_ECU_CLS_Tx_4_message_Missing_Message: provided-interface=DiagnosticMonitor
      EvtInfo_Radar_Performance_Capability_Algorithm_Based_Failure: provided-interface=DiagnosticInfo
      Event_Radar_Performance_Capability_Algorithm_Based_Failure: provided-interface=DiagnosticMonitor
      EvtInfo_Radar_AutoAlignment_Range_Alignment_or_Adjustement_Incorrect: provided-interface=DiagnosticInfo
      Event_Radar_AutoAlignment_Range_Alignment_or_Adjustement_Incorrect: provided-interface=DiagnosticMonitor
      EvtInfo_EMS_ECU_CCVS1_erratic_communication_Erractic: provided-interface=DiagnosticInfo
      Event_EMS_ECU_CCVS1_erratic_communication_Erractic: provided-interface=DiagnosticMonitor
      EvtInfo_Radar_System_Battery_Low_Voltage_System_Voltage_Low: provided-interface=DiagnosticInfo
      Event_Radar_System_Battery_Low_Voltage_System_Voltage_Low: provided-interface=DiagnosticMonitor
      EvtInfo_Radar_SMC_General_Checksum_Failure: provided-interface=DiagnosticInfo
      Event_Radar_SMC_General_Checksum_Failure: provided-interface=DiagnosticMonitor
      EvtInfo_Radar_Pin_Position_Wrong_Mounting_Position: provided-interface=DiagnosticInfo
      Event_Radar_Pin_Position_Wrong_Mounting_Position: provided-interface=DiagnosticMonitor
      EvtInfo_VDC2_message_Lateral_Accleration_Invalid_Serial_Data_Received: provided-interface=DiagnosticInfo
      Event_VDC2_message_Lateral_Accleration_Invalid_Serial_Data_Received: provided-interface=DiagnosticMonitor
      EvtInfo_ADAS_FN_STS_message_BSIS_FN_Switch_STS_Invalid_Serial_Data_Received: provided-interface=DiagnosticInfo
      Event_ADAS_FN_STS_message_BSIS_FN_Switch_STS_Invalid_Serial_Data_Received: provided-interface=DiagnosticMonitor
      EvtInfo_Radar_AutoAlignment_Misalignment_Performance_or_Incorrect_Operation: provided-interface=DiagnosticInfo
      Event_Radar_AutoAlignment_Misalignment_Performance_or_Incorrect_Operation: provided-interface=DiagnosticMonitor
      EvtInfo_ESC_ECU_VDC2_erratic_communication_Erratic: provided-interface=DiagnosticInfo
      Event_ESC_ECU_VDC2_erratic_communication_Erratic: provided-interface=DiagnosticMonitor
      EvtInfo_Application_Interface_Lookup_Performance_or_Incorrect_Operation: provided-interface=DiagnosticInfo
      Event_Application_Interface_Lookup_Performance_or_Incorrect_Operation: provided-interface=DiagnosticMonitor
      EvtInfo_EMS_ECU_VD_message_Missing_Message: provided-interface=DiagnosticInfo
      Event_EMS_ECU_VD_message_Missing_Message: provided-interface=DiagnosticMonitor
      EvtInfo_Radar_Platform_Time_System_Programming_Failure: provided-interface=DiagnosticInfo
      Event_Radar_Platform_Time_System_Programming_Failure: provided-interface=DiagnosticMonitor
      EvtInfo_OEL_message_Turn_Signal_Switch_Invalid_Serial_Data_Received: provided-interface=DiagnosticInfo
      Event_OEL_message_Turn_Signal_Switch_Invalid_Serial_Data_Received: provided-interface=DiagnosticMonitor
      EvtInfo_Radar_calibration_Calibration_or_Paramater_Memory_Failure: provided-interface=DiagnosticInfo
      Event_Radar_calibration_Calibration_or_Paramater_Memory_Failure: provided-interface=DiagnosticMonitor
      GeneralEvtInfo: provided-interface=GeneralDiagnosticInfo
      EvtInfo_DemEventParameter: provided-interface=DiagnosticInfo
      Event_DemEventParameter: provided-interface=DiagnosticMonitor
    behavior DemSatellite_Invalid_OsApplicationInternalBehavior: handle-termination-and-restart=NO-SUPPORT, included-data-type-set=data-type=[Dem_EventIdType, Dem_BufferLengthType, Dcm_NegativeResponseCodeType, Dem_RatioIdType, Dem_EventStatusType, Dem_UdsStatusByteType, Dem_DTCFormatType, Dem_InitMonitorReasonType, Dem_OperationCycleStateType, Dem_DTCStatusMaskType, Dem_IndicatorStatusType, Dem_MaxDataValueType, Dem_DTCKindType, Dem_DTCGroupType, Dem_IumprDenomCondIdType, Dem_IumprDenomCondStatusType, Dem_DebounceResetStatusType, Dem_DebouncingStateType, Dem_IumprReadinessGroupType, Dem_DTRControlType, Dem_DTCSeverityType, Dem_MonitorStatusType]
      timing event Timer_Dem_SatelliteMainFunction: start-on-event=Dem_SatelliteMainFunction, period=0.01
      1375 x operation invoked event:
        OpEventGetEventUdsStatus_GetEventUdsStatus_EvtInfo_SAS_message_Steering_Wheel_Angle_Invalid_Serial_Data_Received: start-on-event=DemSatellite_Invalid_OsApplicationInternalBehavior/GetEventUdsStatus, operation=EvtInfo_SAS_message_Steering_Wheel_Angle_Invalid_Serial_Data_Received.GetEventUdsStatus
        OpEventGetEventUdsStatus_GetEventUdsStatus_Event_SAS_message_Steering_Wheel_Angle_Invalid_Serial_Data_Received: start-on-event=DemSatellite_Invalid_OsApplicationInternalBehavior/GetEventUdsStatus, operation=Event_SAS_message_Steering_Wheel_Angle_Invalid_Serial_Data_Received.GetEventUdsStatus
        OpEventGetEventUdsStatus_GetEventUdsStatus_EvtInfo_AT_AMT_ETC2_message_Transcurrent_gear_Invalid_Serial_Data_Received: start-on-event=DemSatellite_Invalid_OsApplicationInternalBehavior/GetEventUdsStatus, operation=EvtInfo_AT_AMT_ETC2_message_Transcurrent_gear_Invalid_Serial_Data_Received.GetEventUdsStatus
        OpEventGetEventUdsStatus_GetEventUdsStatus_Event_AT_AMT_ETC2_message_Transcurrent_gear_Invalid_Serial_Data_Received: start-on-event=DemSatellite_Invalid_OsApplicationInternalBehavior/GetEventUdsStatus, operation=Event_AT_AMT_ETC2_message_Transcurrent_gear_Invalid_Serial_Data_Received.GetEventUdsStatus
        OpEventGetEventUdsStatus_GetEventUdsStatus_EvtInfo_Radar_AutoAlignment_Algorithm_Signal_Calculation_Failure: start-on-event=DemSatellite_Invalid_OsApplicationInternalBehavior/GetEventUdsStatus, operation=EvtInfo_Radar_AutoAlignment_Algorithm_Signal_Calculation_Failure.GetEventUdsStatus
        OpEventGetEventUdsStatus_GetEventUdsStatus_Event_Radar_AutoAlignment_Algorithm_Signal_Calculation_Failure: start-on-event=DemSatellite_Invalid_OsApplicationInternalBehavior/GetEventUdsStatus, operation=Event_Radar_AutoAlignment_Algorithm_Signal_Calculation_Failure.GetEventUdsStatus
        OpEventGetEventUdsStatus_GetEventUdsStatus_EvtInfo_Vehicle_DataSet_Not_Configured: start-on-event=DemSatellite_Invalid_OsApplicationInternalBehavior/GetEventUdsStatus, operation=EvtInfo_Vehicle_DataSet_Not_Configured.GetEventUdsStatus
        OpEventGetEventUdsStatus_GetEventUdsStatus_Event_Vehicle_DataSet_Not_Configured: start-on-event=DemSatellite_Invalid_OsApplicationInternalBehavior/GetEventUdsStatus, operation=Event_Vehicle_DataSet_Not_Configured.GetEventUdsStatus
        OpEventGetEventUdsStatus_GetEventUdsStatus_EvtInfo_Radar_Module_System_Internal_Failure: start-on-event=DemSatellite_Invalid_OsApplicationInternalBehavior/GetEventUdsStatus, operation=EvtInfo_Radar_Module_System_Internal_Failure.GetEventUdsStatus
        OpEventGetEventUdsStatus_GetEventUdsStatus_Event_Radar_Module_System_Internal_Failure: start-on-event=DemSatellite_Invalid_OsApplicationInternalBehavior/GetEventUdsStatus, operation=Event_Radar_Module_System_Internal_Failure.GetEventUdsStatus
        OpEventGetEventUdsStatus_GetEventUdsStatus_EvtInfo_Radar_MMIC_Component_Failure: start-on-event=DemSatellite_Invalid_OsApplicationInternalBehavior/GetEventUdsStatus, operation=EvtInfo_Radar_MMIC_Component_Failure.GetEventUdsStatus
        OpEventGetEventUdsStatus_GetEventUdsStatus_Event_Radar_MMIC_Component_Failure: start-on-event=DemSatellite_Invalid_OsApplicationInternalBehavior/GetEventUdsStatus, operation=Event_Radar_MMIC_Component_Failure.GetEventUdsStatus
        OpEventGetEventUdsStatus_GetEventUdsStatus_EvtInfo_Radar_Module_General_Memory_Failure: start-on-event=DemSatellite_Invalid_OsApplicationInternalBehavior/GetEventUdsStatus, operation=EvtInfo_Radar_Module_General_Memory_Failure.GetEventUdsStatus
        OpEventGetEventUdsStatus_GetEventUdsStatus_Event_Radar_Module_General_Memory_Failure: start-on-event=DemSatellite_Invalid_OsApplicationInternalBehavior/GetEventUdsStatus, operation=Event_Radar_Module_General_Memory_Failure.GetEventUdsStatus
        OpEventGetEventUdsStatus_GetEventUdsStatus_EvtInfo_Radar_System_Battery_High_Voltage_System_Voltage_High: start-on-event=DemSatellite_Invalid_OsApplicationInternalBehavior/GetEventUdsStatus, operation=EvtInfo_Radar_System_Battery_High_Voltage_System_Voltage_High.GetEventUdsStatus
        OpEventGetEventUdsStatus_GetEventUdsStatus_Event_Radar_System_Battery_High_Voltage_System_Voltage_High: start-on-event=DemSatellite_Invalid_OsApplicationInternalBehavior/GetEventUdsStatus, operation=Event_Radar_System_Battery_High_Voltage_System_Voltage_High.GetEventUdsStatus
        OpEventGetEventUdsStatus_GetEventUdsStatus_EvtInfo_CCVS1_message_Vehicle_Speed_Invalid_Serial_Data_Received: start-on-event=DemSatellite_Invalid_OsApplicationInternalBehavior/GetEventUdsStatus, operation=EvtInfo_CCVS1_message_Vehicle_Speed_Invalid_Serial_Data_Received.GetEventUdsStatus
        OpEventGetEventUdsStatus_GetEventUdsStatus_Event_CCVS1_message_Vehicle_Speed_Invalid_Serial_Data_Received: start-on-event=DemSatellite_Invalid_OsApplicationInternalBehavior/GetEventUdsStatus, operation=Event_CCVS1_message_Vehicle_Speed_Invalid_Serial_Data_Received.GetEventUdsStatus
        OpEventGetEventUdsStatus_GetEventUdsStatus_EvtInfo_EMS_ECU_VD_erratic_communication_Erratic: start-on-event=DemSatellite_Invalid_OsApplicationInternalBehavior/GetEventUdsStatus, operation=EvtInfo_EMS_ECU_VD_erratic_communication_Erratic.GetEventUdsStatus
        OpEventGetEventUdsStatus_GetEventUdsStatus_Event_EMS_ECU_VD_erratic_communication_Erratic: start-on-event=DemSatellite_Invalid_OsApplicationInternalBehavior/GetEventUdsStatus, operation=Event_EMS_ECU_VD_erratic_communication_Erratic.GetEventUdsStatus
        OpEventGetEventUdsStatus_GetEventUdsStatus_EvtInfo_EMS_ECU_ETC2_00_message_Missing_Message: start-on-event=DemSatellite_Invalid_OsApplicationInternalBehavior/GetEventUdsStatus, operation=EvtInfo_EMS_ECU_ETC2_00_message_Missing_Message.GetEventUdsStatus
        OpEventGetEventUdsStatus_GetEventUdsStatus_Event_EMS_ECU_ETC2_00_message_Missing_Message: start-on-event=DemSatellite_Invalid_OsApplicationInternalBehavior/GetEventUdsStatus, operation=Event_EMS_ECU_ETC2_00_message_Missing_Message.GetEventUdsStatus
        OpEventGetEventUdsStatus_GetEventUdsStatus_EvtInfo_Cluster_ECU_CLS_Tx_16_message_Missing_Message: start-on-event=DemSatellite_Invalid_OsApplicationInternalBehavior/GetEventUdsStatus, operation=EvtInfo_Cluster_ECU_CLS_Tx_16_message_Missing_Message.GetEventUdsStatus
        OpEventGetEventUdsStatus_GetEventUdsStatus_Event_Cluster_ECU_CLS_Tx_16_message_Missing_Message: start-on-event=DemSatellite_Invalid_OsApplicationInternalBehavior/GetEventUdsStatus, operation=Event_Cluster_ECU_CLS_Tx_16_message_Missing_Message.GetEventUdsStatus
        OpEventGetEventUdsStatus_GetEventUdsStatus_EvtInfo_Exceeded_Security_Access_0x27_Attempt_Threshold_Authentication_Failure: start-on-event=DemSatellite_Invalid_OsApplicationInternalBehavior/GetEventUdsStatus, operation=EvtInfo_Exceeded_Security_Access_0x27_Attempt_Threshold_Authentication_Failure.GetEventUdsStatus
        OpEventGetEventUdsStatus_GetEventUdsStatus_Event_Exceeded_Security_Access_0x27_Attempt_Threshold_Authentication_Failure: start-on-event=DemSatellite_Invalid_OsApplicationInternalBehavior/GetEventUdsStatus, operation=Event_Exceeded_Security_Access_0x27_Attempt_Threshold_Authentication_Failure.GetEventUdsStatus
        OpEventGetEventUdsStatus_GetEventUdsStatus_EvtInfo_Front_Left_Side_Radar_value_of_signal_protection_calculation_Incorrect: start-on-event=DemSatellite_Invalid_OsApplicationInternalBehavior/GetEventUdsStatus, operation=EvtInfo_Front_Left_Side_Radar_value_of_signal_protection_calculation_Incorrect.GetEventUdsStatus
        OpEventGetEventUdsStatus_GetEventUdsStatus_Event_Front_Left_Side_Radar_value_of_signal_protection_calculation_Incorrect: start-on-event=DemSatellite_Invalid_OsApplicationInternalBehavior/GetEventUdsStatus, operation=Event_Front_Left_Side_Radar_value_of_signal_protection_calculation_Incorrect.GetEventUdsStatus
        OpEventGetEventUdsStatus_GetEventUdsStatus_EvtInfo_AT_AMT_ETC2_erratic_communication_Erratic: start-on-event=DemSatellite_Invalid_OsApplicationInternalBehavior/GetEventUdsStatus, operation=EvtInfo_AT_AMT_ETC2_erratic_communication_Erratic.GetEventUdsStatus
        OpEventGetEventUdsStatus_GetEventUdsStatus_Event_AT_AMT_ETC2_erratic_communication_Erratic: start-on-event=DemSatellite_Invalid_OsApplicationInternalBehavior/GetEventUdsStatus, operation=Event_AT_AMT_ETC2_erratic_communication_Erratic.GetEventUdsStatus
        OpEventGetEventUdsStatus_GetEventUdsStatus_EvtInfo_VCAN_Communication_Bus_Off: start-on-event=DemSatellite_Invalid_OsApplicationInternalBehavior/GetEventUdsStatus, operation=EvtInfo_VCAN_Communication_Bus_Off.GetEventUdsStatus
        OpEventGetEventUdsStatus_GetEventUdsStatus_Event_VCAN_Communication_Bus_Off: start-on-event=DemSatellite_Invalid_OsApplicationInternalBehavior/GetEventUdsStatus, operation=Event_VCAN_Communication_Bus_Off.GetEventUdsStatus
        OpEventGetEventUdsStatus_GetEventUdsStatus_EvtInfo_VDC2_message_LongitudinalAcceleration_Invalid_Serial_Data_Received: start-on-event=DemSatellite_Invalid_OsApplicationInternalBehavior/GetEventUdsStatus, operation=EvtInfo_VDC2_message_LongitudinalAcceleration_Invalid_Serial_Data_Received.GetEventUdsStatus
        OpEventGetEventUdsStatus_GetEventUdsStatus_Event_VDC2_message_LongitudinalAcceleration_Invalid_Serial_Data_Received: start-on-event=DemSatellite_Invalid_OsApplicationInternalBehavior/GetEventUdsStatus, operation=Event_VDC2_message_LongitudinalAcceleration_Invalid_Serial_Data_Received.GetEventUdsStatus
        OpEventGetEventUdsStatus_GetEventUdsStatus_EvtInfo_Radar_MMIC_RFBIST_Component_Internal_Failure: start-on-event=DemSatellite_Invalid_OsApplicationInternalBehavior/GetEventUdsStatus, operation=EvtInfo_Radar_MMIC_RFBIST_Component_Internal_Failure.GetEventUdsStatus
        OpEventGetEventUdsStatus_GetEventUdsStatus_Event_Radar_MMIC_RFBIST_Component_Internal_Failure: start-on-event=DemSatellite_Invalid_OsApplicationInternalBehavior/GetEventUdsStatus, operation=Event_Radar_MMIC_RFBIST_Component_Internal_Failure.GetEventUdsStatus
        OpEventGetEventUdsStatus_GetEventUdsStatus_EvtInfo_Radar_Initial_Alignment_Missing_Calibration: start-on-event=DemSatellite_Invalid_OsApplicationInternalBehavior/GetEventUdsStatus, operation=EvtInfo_Radar_Initial_Alignment_Missing_Calibration.GetEventUdsStatus
        OpEventGetEventUdsStatus_GetEventUdsStatus_Event_Radar_Initial_Alignment_Missing_Calibration: start-on-event=DemSatellite_Invalid_OsApplicationInternalBehavior/GetEventUdsStatus, operation=Event_Radar_Initial_Alignment_Missing_Calibration.GetEventUdsStatus
        OpEventGetEventUdsStatus_GetEventUdsStatus_EvtInfo_Cluster_ECU_OEL_message_Missing_Message: start-on-event=DemSatellite_Invalid_OsApplicationInternalBehavior/GetEventUdsStatus, operation=EvtInfo_Cluster_ECU_OEL_message_Missing_Message.GetEventUdsStatus
        OpEventGetEventUdsStatus_GetEventUdsStatus_Event_Cluster_ECU_OEL_message_Missing_Message: start-on-event=DemSatellite_Invalid_OsApplicationInternalBehavior/GetEventUdsStatus, operation=Event_Cluster_ECU_OEL_message_Missing_Message.GetEventUdsStatus
        OpEventGetEventUdsStatus_GetEventUdsStatus_EvtInfo_AT_AMT_ECU_ETC2_03_message_Missing_Message: start-on-event=DemSatellite_Invalid_OsApplicationInternalBehavior/GetEventUdsStatus, operation=EvtInfo_AT_AMT_ECU_ETC2_03_message_Missing_Message.GetEventUdsStatus
        OpEventGetEventUdsStatus_GetEventUdsStatus_Event_AT_AMT_ECU_ETC2_03_message_Missing_Message: start-on-event=DemSatellite_Invalid_OsApplicationInternalBehavior/GetEventUdsStatus, operation=Event_AT_AMT_ECU_ETC2_03_message_Missing_Message.GetEventUdsStatus
        OpEventGetEventUdsStatus_GetEventUdsStatus_EvtInfo_ADAS_FN_STS_message_MOIS_FN_Switch_STS_Invalid_Serial_Data_Received: start-on-event=DemSatellite_Invalid_OsApplicationInternalBehavior/GetEventUdsStatus, operation=EvtInfo_ADAS_FN_STS_message_MOIS_FN_Switch_STS_Invalid_Serial_Data_Received.GetEventUdsStatus
        OpEventGetEventUdsStatus_GetEventUdsStatus_Event_ADAS_FN_STS_message_MOIS_FN_Switch_STS_Invalid_Serial_Data_Received: start-on-event=DemSatellite_Invalid_OsApplicationInternalBehavior/GetEventUdsStatus, operation=Event_ADAS_FN_STS_message_MOIS_FN_Switch_STS_Invalid_Serial_Data_Received.GetEventUdsStatus
        OpEventGetEventUdsStatus_GetEventUdsStatus_EvtInfo_Radar_Module_Over_Temperature: start-on-event=DemSatellite_Invalid_OsApplicationInternalBehavior/GetEventUdsStatus, operation=EvtInfo_Radar_Module_Over_Temperature.GetEventUdsStatus
        OpEventGetEventUdsStatus_GetEventUdsStatus_Event_Radar_Module_Over_Temperature: start-on-event=DemSatellite_Invalid_OsApplicationInternalBehavior/GetEventUdsStatus, operation=Event_Radar_Module_Over_Temperature.GetEventUdsStatus
        OpEventGetEventUdsStatus_GetEventUdsStatus_EvtInfo_PCAN_TimeSync_Missing_Message: start-on-event=DemSatellite_Invalid_OsApplicationInternalBehavior/GetEventUdsStatus, operation=EvtInfo_PCAN_TimeSync_Missing_Message.GetEventUdsStatus
        OpEventGetEventUdsStatus_GetEventUdsStatus_Event_PCAN_TimeSync_Missing_Message: start-on-event=DemSatellite_Invalid_OsApplicationInternalBehavior/GetEventUdsStatus, operation=Event_PCAN_TimeSync_Missing_Message.GetEventUdsStatus
        OpEventGetEventUdsStatus_GetEventUdsStatus_EvtInfo_Radar_Module_Watchdog_Failure: start-on-event=DemSatellite_Invalid_OsApplicationInternalBehavior/GetEventUdsStatus, operation=EvtInfo_Radar_Module_Watchdog_Failure.GetEventUdsStatus
        OpEventGetEventUdsStatus_GetEventUdsStatus_Event_Radar_Module_Watchdog_Failure: start-on-event=DemSatellite_Invalid_OsApplicationInternalBehavior/GetEventUdsStatus, operation=Event_Radar_Module_Watchdog_Failure.GetEventUdsStatus
        OpEventGetEventUdsStatus_GetEventUdsStatus_EvtInfo_SAS_ECU_SAS_message_Missing_Message: start-on-event=DemSatellite_Invalid_OsApplicationInternalBehavior/GetEventUdsStatus, operation=EvtInfo_SAS_ECU_SAS_message_Missing_Message.GetEventUdsStatus
        OpEventGetEventUdsStatus_GetEventUdsStatus_Event_SAS_ECU_SAS_message_Missing_Message: start-on-event=DemSatellite_Invalid_OsApplicationInternalBehavior/GetEventUdsStatus, operation=Event_SAS_ECU_SAS_message_Missing_Message.GetEventUdsStatus
        OpEventGetEventUdsStatus_GetEventUdsStatus_EvtInfo_ECU_NVM_Corruption_Program_memory_Failure: start-on-event=DemSatellite_Invalid_OsApplicationInternalBehavior/GetEventUdsStatus, operation=EvtInfo_ECU_NVM_Corruption_Program_memory_Failure.GetEventUdsStatus
        OpEventGetEventUdsStatus_GetEventUdsStatus_Event_ECU_NVM_Corruption_Program_memory_Failure: start-on-event=DemSatellite_Invalid_OsApplicationInternalBehavior/GetEventUdsStatus, operation=Event_ECU_NVM_Corruption_Program_memory_Failure.GetEventUdsStatus
        OpEventGetEventUdsStatus_GetEventUdsStatus_EvtInfo_Cluster_ECU_TD_message_Missing_Message: start-on-event=DemSatellite_Invalid_OsApplicationInternalBehavior/GetEventUdsStatus, operation=EvtInfo_Cluster_ECU_TD_message_Missing_Message.GetEventUdsStatus
        OpEventGetEventUdsStatus_GetEventUdsStatus_Event_Cluster_ECU_TD_message_Missing_Message: start-on-event=DemSatellite_Invalid_OsApplicationInternalBehavior/GetEventUdsStatus, operation=Event_Cluster_ECU_TD_message_Missing_Message.GetEventUdsStatus
        OpEventGetEventUdsStatus_GetEventUdsStatus_EvtInfo_PCAN_Communication_Bus_Off: start-on-event=DemSatellite_Invalid_OsApplicationInternalBehavior/GetEventUdsStatus, operation=EvtInfo_PCAN_Communication_Bus_Off.GetEventUdsStatus
        OpEventGetEventUdsStatus_GetEventUdsStatus_Event_PCAN_Communication_Bus_Off: start-on-event=DemSatellite_Invalid_OsApplicationInternalBehavior/GetEventUdsStatus, operation=Event_PCAN_Communication_Bus_Off.GetEventUdsStatus
        OpEventGetEventUdsStatus_GetEventUdsStatus_EvtInfo_Front_Left_Side_Radar_Missing_Message: start-on-event=DemSatellite_Invalid_OsApplicationInternalBehavior/GetEventUdsStatus, operation=EvtInfo_Front_Left_Side_Radar_Missing_Message.GetEventUdsStatus
        OpEventGetEventUdsStatus_GetEventUdsStatus_Event_Front_Left_Side_Radar_Missing_Message: start-on-event=DemSatellite_Invalid_OsApplicationInternalBehavior/GetEventUdsStatus, operation=Event_Front_Left_Side_Radar_Missing_Message.GetEventUdsStatus
        OpEventGetEventUdsStatus_GetEventUdsStatus_EvtInfo_Manual_ETC2_message_Transcurrent_gear_Invalid_Serial_Data_Received: start-on-event=DemSatellite_Invalid_OsApplicationInternalBehavior/GetEventUdsStatus, operation=EvtInfo_Manual_ETC2_message_Transcurrent_gear_Invalid_Serial_Data_Received.GetEventUdsStatus
        OpEventGetEventUdsStatus_GetEventUdsStatus_Event_Manual_ETC2_message_Transcurrent_gear_Invalid_Serial_Data_Received: start-on-event=DemSatellite_Invalid_OsApplicationInternalBehavior/GetEventUdsStatus, operation=Event_Manual_ETC2_message_Transcurrent_gear_Invalid_Serial_Data_Received.GetEventUdsStatus
        OpEventGetEventUdsStatus_GetEventUdsStatus_EvtInfo_SAS_ECU_erratic_communication_Erratic: start-on-event=DemSatellite_Invalid_OsApplicationInternalBehavior/GetEventUdsStatus, operation=EvtInfo_SAS_ECU_erratic_communication_Erratic.GetEventUdsStatus
        OpEventGetEventUdsStatus_GetEventUdsStatus_Event_SAS_ECU_erratic_communication_Erratic: start-on-event=DemSatellite_Invalid_OsApplicationInternalBehavior/GetEventUdsStatus, operation=Event_SAS_ECU_erratic_communication_Erratic.GetEventUdsStatus
        OpEventGetEventUdsStatus_GetEventUdsStatus_EvtInfo_VDC2_message_Yaw_rate_Invalid_Serial_Data_Received: start-on-event=DemSatellite_Invalid_OsApplicationInternalBehavior/GetEventUdsStatus, operation=EvtInfo_VDC2_message_Yaw_rate_Invalid_Serial_Data_Received.GetEventUdsStatus
        OpEventGetEventUdsStatus_GetEventUdsStatus_Event_VDC2_message_Yaw_rate_Invalid_Serial_Data_Received: start-on-event=DemSatellite_Invalid_OsApplicationInternalBehavior/GetEventUdsStatus, operation=Event_VDC2_message_Yaw_rate_Invalid_Serial_Data_Received.GetEventUdsStatus
        OpEventGetEventUdsStatus_GetEventUdsStatus_EvtInfo_Cluster_ECU_TD_erratic_communication_Erratic: start-on-event=DemSatellite_Invalid_OsApplicationInternalBehavior/GetEventUdsStatus, operation=EvtInfo_Cluster_ECU_TD_erratic_communication_Erratic.GetEventUdsStatus
        OpEventGetEventUdsStatus_GetEventUdsStatus_Event_Cluster_ECU_TD_erratic_communication_Erratic: start-on-event=DemSatellite_Invalid_OsApplicationInternalBehavior/GetEventUdsStatus, operation=Event_Cluster_ECU_TD_erratic_communication_Erratic.GetEventUdsStatus
        OpEventGetEventUdsStatus_GetEventUdsStatus_EvtInfo_EMS_ECU_CCVS1_message_Missing_Message: start-on-event=DemSatellite_Invalid_OsApplicationInternalBehavior/GetEventUdsStatus, operation=EvtInfo_EMS_ECU_CCVS1_message_Missing_Message.GetEventUdsStatus
        OpEventGetEventUdsStatus_GetEventUdsStatus_Event_EMS_ECU_CCVS1_message_Missing_Message: start-on-event=DemSatellite_Invalid_OsApplicationInternalBehavior/GetEventUdsStatus, operation=Event_EMS_ECU_CCVS1_message_Missing_Message.GetEventUdsStatus
        OpEventGetEventUdsStatus_GetEventUdsStatus_EvtInfo_Radar_Mounting_Orientation_Incorrect_Assembly: start-on-event=DemSatellite_Invalid_OsApplicationInternalBehavior/GetEventUdsStatus, operation=EvtInfo_Radar_Mounting_Orientation_Incorrect_Assembly.GetEventUdsStatus
        OpEventGetEventUdsStatus_GetEventUdsStatus_Event_Radar_Mounting_Orientation_Incorrect_Assembly: start-on-event=DemSatellite_Invalid_OsApplicationInternalBehavior/GetEventUdsStatus, operation=Event_Radar_Mounting_Orientation_Incorrect_Assembly.GetEventUdsStatus
        OpEventGetEventUdsStatus_GetEventUdsStatus_EvtInfo_EMS_ECU_ETC2_erratic_communication_Erractic: start-on-event=DemSatellite_Invalid_OsApplicationInternalBehavior/GetEventUdsStatus, operation=EvtInfo_EMS_ECU_ETC2_erratic_communication_Erractic.GetEventUdsStatus
        OpEventGetEventUdsStatus_GetEventUdsStatus_Event_EMS_ECU_ETC2_erratic_communication_Erractic: start-on-event=DemSatellite_Invalid_OsApplicationInternalBehavior/GetEventUdsStatus, operation=Event_EMS_ECU_ETC2_erratic_communication_Erractic.GetEventUdsStatus
        OpEventGetEventUdsStatus_GetEventUdsStatus_EvtInfo_Cluster_ECU_ADAS_FN_STS_erratic_communication_Erratic: start-on-event=DemSatellite_Invalid_OsApplicationInternalBehavior/GetEventUdsStatus, operation=EvtInfo_Cluster_ECU_ADAS_FN_STS_erratic_communication_Erratic.GetEventUdsStatus
        OpEventGetEventUdsStatus_GetEventUdsStatus_Event_Cluster_ECU_ADAS_FN_STS_erratic_communication_Erratic: start-on-event=DemSatellite_Invalid_OsApplicationInternalBehavior/GetEventUdsStatus, operation=Event_Cluster_ECU_ADAS_FN_STS_erratic_communication_Erratic.GetEventUdsStatus
        OpEventGetEventUdsStatus_GetEventUdsStatus_EvtInfo_ESC_ECU_VDC2_message_Missing_Message: start-on-event=DemSatellite_Invalid_OsApplicationInternalBehavior/GetEventUdsStatus, operation=EvtInfo_ESC_ECU_VDC2_message_Missing_Message.GetEventUdsStatus
        OpEventGetEventUdsStatus_GetEventUdsStatus_Event_ESC_ECU_VDC2_message_Missing_Message: start-on-event=DemSatellite_Invalid_OsApplicationInternalBehavior/GetEventUdsStatus, operation=Event_ESC_ECU_VDC2_message_Missing_Message.GetEventUdsStatus
        OpEventGetEventUdsStatus_GetEventUdsStatus_EvtInfo_CLS_TX_16_message_Transmission_Type_info_Invalid_Serial_Data_Received: start-on-event=DemSatellite_Invalid_OsApplicationInternalBehavior/GetEventUdsStatus, operation=EvtInfo_CLS_TX_16_message_Transmission_Type_info_Invalid_Serial_Data_Received.GetEventUdsStatus
        OpEventGetEventUdsStatus_GetEventUdsStatus_Event_CLS_TX_16_message_Transmission_Type_info_Invalid_Serial_Data_Received: start-on-event=DemSatellite_Invalid_OsApplicationInternalBehavior/GetEventUdsStatus, operation=Event_CLS_TX_16_message_Transmission_Type_info_Invalid_Serial_Data_Received.GetEventUdsStatus
        OpEventGetEventUdsStatus_GetEventUdsStatus_EvtInfo_Cluster_ECU_CLS_Tx_4_erratic_communication_Erratic: start-on-event=DemSatellite_Invalid_OsApplicationInternalBehavior/GetEventUdsStatus, operation=EvtInfo_Cluster_ECU_CLS_Tx_4_erratic_communication_Erratic.GetEventUdsStatus
        OpEventGetEventUdsStatus_GetEventUdsStatus_Event_Cluster_ECU_CLS_Tx_4_erratic_communication_Erratic: start-on-event=DemSatellite_Invalid_OsApplicationInternalBehavior/GetEventUdsStatus, operation=Event_Cluster_ECU_CLS_Tx_4_erratic_communication_Erratic.GetEventUdsStatus
        OpEventGetEventUdsStatus_GetEventUdsStatus_EvtInfo_Cluster_ECU_ADAS_FN_STS_message_Missing_Message: start-on-event=DemSatellite_Invalid_OsApplicationInternalBehavior/GetEventUdsStatus, operation=EvtInfo_Cluster_ECU_ADAS_FN_STS_message_Missing_Message.GetEventUdsStatus
        OpEventGetEventUdsStatus_GetEventUdsStatus_Event_Cluster_ECU_ADAS_FN_STS_message_Missing_Message: start-on-event=DemSatellite_Invalid_OsApplicationInternalBehavior/GetEventUdsStatus, operation=Event_Cluster_ECU_ADAS_FN_STS_message_Missing_Message.GetEventUdsStatus
        OpEventGetEventUdsStatus_GetEventUdsStatus_EvtInfo_Vehicle_Dataset_value_of_signal_protection_calculation_Incorrect: start-on-event=DemSatellite_Invalid_OsApplicationInternalBehavior/GetEventUdsStatus, operation=EvtInfo_Vehicle_Dataset_value_of_signal_protection_calculation_Incorrect.GetEventUdsStatus
        OpEventGetEventUdsStatus_GetEventUdsStatus_Event_Vehicle_Dataset_value_of_signal_protection_calculation_Incorrect: start-on-event=DemSatellite_Invalid_OsApplicationInternalBehavior/GetEventUdsStatus, operation=Event_Vehicle_Dataset_value_of_signal_protection_calculation_Incorrect.GetEventUdsStatus
        OpEventGetEventUdsStatus_GetEventUdsStatus_EvtInfo_Cluster_ECU_CLS_Tx_16_erratic_communication_Erratic: start-on-event=DemSatellite_Invalid_OsApplicationInternalBehavior/GetEventUdsStatus, operation=EvtInfo_Cluster_ECU_CLS_Tx_16_erratic_communication_Erratic.GetEventUdsStatus
        OpEventGetEventUdsStatus_GetEventUdsStatus_Event_Cluster_ECU_CLS_Tx_16_erratic_communication_Erratic: start-on-event=DemSatellite_Invalid_OsApplicationInternalBehavior/GetEventUdsStatus, operation=Event_Cluster_ECU_CLS_Tx_16_erratic_communication_Erratic.GetEventUdsStatus
        OpEventGetEventUdsStatus_GetEventUdsStatus_EvtInfo_Cluster_ECU_OEL_erratic_communication_Erratic: start-on-event=DemSatellite_Invalid_OsApplicationInternalBehavior/GetEventUdsStatus, operation=EvtInfo_Cluster_ECU_OEL_erratic_communication_Erratic.GetEventUdsStatus
        OpEventGetEventUdsStatus_GetEventUdsStatus_Event_Cluster_ECU_OEL_erratic_communication_Erratic: start-on-event=DemSatellite_Invalid_OsApplicationInternalBehavior/GetEventUdsStatus, operation=Event_Cluster_ECU_OEL_erratic_communication_Erratic.GetEventUdsStatus
        OpEventGetEventUdsStatus_GetEventUdsStatus_EvtInfo_Cluster_ECU_CLS_Tx_4_message_Missing_Message: start-on-event=DemSatellite_Invalid_OsApplicationInternalBehavior/GetEventUdsStatus, operation=EvtInfo_Cluster_ECU_CLS_Tx_4_message_Missing_Message.GetEventUdsStatus
        OpEventGetEventUdsStatus_GetEventUdsStatus_Event_Cluster_ECU_CLS_Tx_4_message_Missing_Message: start-on-event=DemSatellite_Invalid_OsApplicationInternalBehavior/GetEventUdsStatus, operation=Event_Cluster_ECU_CLS_Tx_4_message_Missing_Message.GetEventUdsStatus
        OpEventGetEventUdsStatus_GetEventUdsStatus_EvtInfo_Radar_Performance_Capability_Algorithm_Based_Failure: start-on-event=DemSatellite_Invalid_OsApplicationInternalBehavior/GetEventUdsStatus, operation=EvtInfo_Radar_Performance_Capability_Algorithm_Based_Failure.GetEventUdsStatus
        OpEventGetEventUdsStatus_GetEventUdsStatus_Event_Radar_Performance_Capability_Algorithm_Based_Failure: start-on-event=DemSatellite_Invalid_OsApplicationInternalBehavior/GetEventUdsStatus, operation=Event_Radar_Performance_Capability_Algorithm_Based_Failure.GetEventUdsStatus
        OpEventGetEventUdsStatus_GetEventUdsStatus_EvtInfo_Radar_AutoAlignment_Range_Alignment_or_Adjustement_Incorrect: start-on-event=DemSatellite_Invalid_OsApplicationInternalBehavior/GetEventUdsStatus, operation=EvtInfo_Radar_AutoAlignment_Range_Alignment_or_Adjustement_Incorrect.GetEventUdsStatus
        OpEventGetEventUdsStatus_GetEventUdsStatus_Event_Radar_AutoAlignment_Range_Alignment_or_Adjustement_Incorrect: start-on-event=DemSatellite_Invalid_OsApplicationInternalBehavior/GetEventUdsStatus, operation=Event_Radar_AutoAlignment_Range_Alignment_or_Adjustement_Incorrect.GetEventUdsStatus
        OpEventGetEventUdsStatus_GetEventUdsStatus_EvtInfo_EMS_ECU_CCVS1_erratic_communication_Erractic: start-on-event=DemSatellite_Invalid_OsApplicationInternalBehavior/GetEventUdsStatus, operation=EvtInfo_EMS_ECU_CCVS1_erratic_communication_Erractic.GetEventUdsStatus
        OpEventGetEventUdsStatus_GetEventUdsStatus_Event_EMS_ECU_CCVS1_erratic_communication_Erractic: start-on-event=DemSatellite_Invalid_OsApplicationInternalBehavior/GetEventUdsStatus, operation=Event_EMS_ECU_CCVS1_erratic_communication_Erractic.GetEventUdsStatus
        OpEventGetEventUdsStatus_GetEventUdsStatus_EvtInfo_Radar_System_Battery_Low_Voltage_System_Voltage_Low: start-on-event=DemSatellite_Invalid_OsApplicationInternalBehavior/GetEventUdsStatus, operation=EvtInfo_Radar_System_Battery_Low_Voltage_System_Voltage_Low.GetEventUdsStatus
        OpEventGetEventUdsStatus_GetEventUdsStatus_Event_Radar_System_Battery_Low_Voltage_System_Voltage_Low: start-on-event=DemSatellite_Invalid_OsApplicationInternalBehavior/GetEventUdsStatus, operation=Event_Radar_System_Battery_Low_Voltage_System_Voltage_Low.GetEventUdsStatus
        OpEventGetEventUdsStatus_GetEventUdsStatus_EvtInfo_Radar_SMC_General_Checksum_Failure: start-on-event=DemSatellite_Invalid_OsApplicationInternalBehavior/GetEventUdsStatus, operation=EvtInfo_Radar_SMC_General_Checksum_Failure.GetEventUdsStatus
        OpEventGetEventUdsStatus_GetEventUdsStatus_Event_Radar_SMC_General_Checksum_Failure: start-on-event=DemSatellite_Invalid_OsApplicationInternalBehavior/GetEventUdsStatus, operation=Event_Radar_SMC_General_Checksum_Failure.GetEventUdsStatus
        OpEventGetEventUdsStatus_GetEventUdsStatus_EvtInfo_Radar_Pin_Position_Wrong_Mounting_Position: start-on-event=DemSatellite_Invalid_OsApplicationInternalBehavior/GetEventUdsStatus, operation=EvtInfo_Radar_Pin_Position_Wrong_Mounting_Position.GetEventUdsStatus
        OpEventGetEventUdsStatus_GetEventUdsStatus_Event_Radar_Pin_Position_Wrong_Mounting_Position: start-on-event=DemSatellite_Invalid_OsApplicationInternalBehavior/GetEventUdsStatus, operation=Event_Radar_Pin_Position_Wrong_Mounting_Position.GetEventUdsStatus
        OpEventGetEventUdsStatus_GetEventUdsStatus_EvtInfo_VDC2_message_Lateral_Accleration_Invalid_Serial_Data_Received: start-on-event=DemSatellite_Invalid_OsApplicationInternalBehavior/GetEventUdsStatus, operation=EvtInfo_VDC2_message_Lateral_Accleration_Invalid_Serial_Data_Received.GetEventUdsStatus
        OpEventGetEventUdsStatus_GetEventUdsStatus_Event_VDC2_message_Lateral_Accleration_Invalid_Serial_Data_Received: start-on-event=DemSatellite_Invalid_OsApplicationInternalBehavior/GetEventUdsStatus, operation=Event_VDC2_message_Lateral_Accleration_Invalid_Serial_Data_Received.GetEventUdsStatus
        OpEventGetEventUdsStatus_GetEventUdsStatus_EvtInfo_ADAS_FN_STS_message_BSIS_FN_Switch_STS_Invalid_Serial_Data_Received: start-on-event=DemSatellite_Invalid_OsApplicationInternalBehavior/GetEventUdsStatus, operation=EvtInfo_ADAS_FN_STS_message_BSIS_FN_Switch_STS_Invalid_Serial_Data_Received.GetEventUdsStatus
        OpEventGetEventUdsStatus_GetEventUdsStatus_Event_ADAS_FN_STS_message_BSIS_FN_Switch_STS_Invalid_Serial_Data_Received: start-on-event=DemSatellite_Invalid_OsApplicationInternalBehavior/GetEventUdsStatus, operation=Event_ADAS_FN_STS_message_BSIS_FN_Switch_STS_Invalid_Serial_Data_Received.GetEventUdsStatus
        OpEventGetEventUdsStatus_GetEventUdsStatus_EvtInfo_Radar_AutoAlignment_Misalignment_Performance_or_Incorrect_Operation: start-on-event=DemSatellite_Invalid_OsApplicationInternalBehavior/GetEventUdsStatus, operation=EvtInfo_Radar_AutoAlignment_Misalignment_Performance_or_Incorrect_Operation.GetEventUdsStatus
        OpEventGetEventUdsStatus_GetEventUdsStatus_Event_Radar_AutoAlignment_Misalignment_Performance_or_Incorrect_Operation: start-on-event=DemSatellite_Invalid_OsApplicationInternalBehavior/GetEventUdsStatus, operation=Event_Radar_AutoAlignment_Misalignment_Performance_or_Incorrect_Operation.GetEventUdsStatus
        OpEventGetEventUdsStatus_GetEventUdsStatus_EvtInfo_ESC_ECU_VDC2_erratic_communication_Erratic: start-on-event=DemSatellite_Invalid_OsApplicationInternalBehavior/GetEventUdsStatus, operation=EvtInfo_ESC_ECU_VDC2_erratic_communication_Erratic.GetEventUdsStatus
        OpEventGetEventUdsStatus_GetEventUdsStatus_Event_ESC_ECU_VDC2_erratic_communication_Erratic: start-on-event=DemSatellite_Invalid_OsApplicationInternalBehavior/GetEventUdsStatus, operation=Event_ESC_ECU_VDC2_erratic_communication_Erratic.GetEventUdsStatus
        OpEventGetEventUdsStatus_GetEventUdsStatus_EvtInfo_Application_Interface_Lookup_Performance_or_Incorrect_Operation: start-on-event=DemSatellite_Invalid_OsApplicationInternalBehavior/GetEventUdsStatus, operation=EvtInfo_Application_Interface_Lookup_Performance_or_Incorrect_Operation.GetEventUdsStatus
        OpEventGetEventUdsStatus_GetEventUdsStatus_Event_Application_Interface_Lookup_Performance_or_Incorrect_Operation: start-on-event=DemSatellite_Invalid_OsApplicationInternalBehavior/GetEventUdsStatus, operation=Event_Application_Interface_Lookup_Performance_or_Incorrect_Operation.GetEventUdsStatus
        OpEventGetEventUdsStatus_GetEventUdsStatus_EvtInfo_EMS_ECU_VD_message_Missing_Message: start-on-event=DemSatellite_Invalid_OsApplicationInternalBehavior/GetEventUdsStatus, operation=EvtInfo_EMS_ECU_VD_message_Missing_Message.GetEventUdsStatus
        OpEventGetEventUdsStatus_GetEventUdsStatus_Event_EMS_ECU_VD_message_Missing_Message: start-on-event=DemSatellite_Invalid_OsApplicationInternalBehavior/GetEventUdsStatus, operation=Event_EMS_ECU_VD_message_Missing_Message.GetEventUdsStatus
        OpEventGetEventUdsStatus_GetEventUdsStatus_EvtInfo_Radar_Platform_Time_System_Programming_Failure: start-on-event=DemSatellite_Invalid_OsApplicationInternalBehavior/GetEventUdsStatus, operation=EvtInfo_Radar_Platform_Time_System_Programming_Failure.GetEventUdsStatus
        OpEventGetEventUdsStatus_GetEventUdsStatus_Event_Radar_Platform_Time_System_Programming_Failure: start-on-event=DemSatellite_Invalid_OsApplicationInternalBehavior/GetEventUdsStatus, operation=Event_Radar_Platform_Time_System_Programming_Failure.GetEventUdsStatus
        OpEventGetEventUdsStatus_GetEventUdsStatus_EvtInfo_OEL_message_Turn_Signal_Switch_Invalid_Serial_Data_Received: start-on-event=DemSatellite_Invalid_OsApplicationInternalBehavior/GetEventUdsStatus, operation=EvtInfo_OEL_message_Turn_Signal_Switch_Invalid_Serial_Data_Received.GetEventUdsStatus
        OpEventGetEventUdsStatus_GetEventUdsStatus_Event_OEL_message_Turn_Signal_Switch_Invalid_Serial_Data_Received: start-on-event=DemSatellite_Invalid_OsApplicationInternalBehavior/GetEventUdsStatus, operation=Event_OEL_message_Turn_Signal_Switch_Invalid_Serial_Data_Received.GetEventUdsStatus
        OpEventGetEventUdsStatus_GetEventUdsStatus_EvtInfo_Radar_calibration_Calibration_or_Paramater_Memory_Failure: start-on-event=DemSatellite_Invalid_OsApplicationInternalBehavior/GetEventUdsStatus, operation=EvtInfo_Radar_calibration_Calibration_or_Paramater_Memory_Failure.GetEventUdsStatus
        OpEventGetEventUdsStatus_GetEventUdsStatus_Event_Radar_calibration_Calibration_or_Paramater_Memory_Failure: start-on-event=DemSatellite_Invalid_OsApplicationInternalBehavior/GetEventUdsStatus, operation=Event_Radar_calibration_Calibration_or_Paramater_Memory_Failure.GetEventUdsStatus
        OpEventGetEventUdsStatus_GetEventUdsStatus_GeneralEvtInfo: start-on-event=DemSatellite_Invalid_OsApplicationInternalBehavior/GetEventUdsStatus, operation=GeneralEvtInfo.GetEventUdsStatus
        OpEventGetEventStatus_GetEventStatus_EvtInfo_SAS_message_Steering_Wheel_Angle_Invalid_Serial_Data_Received: start-on-event=DemSatellite_Invalid_OsApplicationInternalBehavior/GetEventStatus, operation=EvtInfo_SAS_message_Steering_Wheel_Angle_Invalid_Serial_Data_Received.GetEventStatus
        OpEventGetEventStatus_GetEventStatus_Event_SAS_message_Steering_Wheel_Angle_Invalid_Serial_Data_Received: start-on-event=DemSatellite_Invalid_OsApplicationInternalBehavior/GetEventStatus, operation=Event_SAS_message_Steering_Wheel_Angle_Invalid_Serial_Data_Received.GetEventStatus
        OpEventGetEventStatus_GetEventStatus_EvtInfo_AT_AMT_ETC2_message_Transcurrent_gear_Invalid_Serial_Data_Received: start-on-event=DemSatellite_Invalid_OsApplicationInternalBehavior/GetEventStatus, operation=EvtInfo_AT_AMT_ETC2_message_Transcurrent_gear_Invalid_Serial_Data_Received.GetEventStatus
        OpEventGetEventStatus_GetEventStatus_Event_AT_AMT_ETC2_message_Transcurrent_gear_Invalid_Serial_Data_Received: start-on-event=DemSatellite_Invalid_OsApplicationInternalBehavior/GetEventStatus, operation=Event_AT_AMT_ETC2_message_Transcurrent_gear_Invalid_Serial_Data_Received.GetEventStatus
        OpEventGetEventStatus_GetEventStatus_EvtInfo_Radar_AutoAlignment_Algorithm_Signal_Calculation_Failure: start-on-event=DemSatellite_Invalid_OsApplicationInternalBehavior/GetEventStatus, operation=EvtInfo_Radar_AutoAlignment_Algorithm_Signal_Calculation_Failure.GetEventStatus
        OpEventGetEventStatus_GetEventStatus_Event_Radar_AutoAlignment_Algorithm_Signal_Calculation_Failure: start-on-event=DemSatellite_Invalid_OsApplicationInternalBehavior/GetEventStatus, operation=Event_Radar_AutoAlignment_Algorithm_Signal_Calculation_Failure.GetEventStatus
        OpEventGetEventStatus_GetEventStatus_EvtInfo_Vehicle_DataSet_Not_Configured: start-on-event=DemSatellite_Invalid_OsApplicationInternalBehavior/GetEventStatus, operation=EvtInfo_Vehicle_DataSet_Not_Configured.GetEventStatus
        OpEventGetEventStatus_GetEventStatus_Event_Vehicle_DataSet_Not_Configured: start-on-event=DemSatellite_Invalid_OsApplicationInternalBehavior/GetEventStatus, operation=Event_Vehicle_DataSet_Not_Configured.GetEventStatus
        OpEventGetEventStatus_GetEventStatus_EvtInfo_Radar_Module_System_Internal_Failure: start-on-event=DemSatellite_Invalid_OsApplicationInternalBehavior/GetEventStatus, operation=EvtInfo_Radar_Module_System_Internal_Failure.GetEventStatus
        OpEventGetEventStatus_GetEventStatus_Event_Radar_Module_System_Internal_Failure: start-on-event=DemSatellite_Invalid_OsApplicationInternalBehavior/GetEventStatus, operation=Event_Radar_Module_System_Internal_Failure.GetEventStatus
        OpEventGetEventStatus_GetEventStatus_EvtInfo_Radar_MMIC_Component_Failure: start-on-event=DemSatellite_Invalid_OsApplicationInternalBehavior/GetEventStatus, operation=EvtInfo_Radar_MMIC_Component_Failure.GetEventStatus
        OpEventGetEventStatus_GetEventStatus_Event_Radar_MMIC_Component_Failure: start-on-event=DemSatellite_Invalid_OsApplicationInternalBehavior/GetEventStatus, operation=Event_Radar_MMIC_Component_Failure.GetEventStatus
        OpEventGetEventStatus_GetEventStatus_EvtInfo_Radar_Module_General_Memory_Failure: start-on-event=DemSatellite_Invalid_OsApplicationInternalBehavior/GetEventStatus, operation=EvtInfo_Radar_Module_General_Memory_Failure.GetEventStatus
        OpEventGetEventStatus_GetEventStatus_Event_Radar_Module_General_Memory_Failure: start-on-event=DemSatellite_Invalid_OsApplicationInternalBehavior/GetEventStatus, operation=Event_Radar_Module_General_Memory_Failure.GetEventStatus
        OpEventGetEventStatus_GetEventStatus_EvtInfo_Radar_System_Battery_High_Voltage_System_Voltage_High: start-on-event=DemSatellite_Invalid_OsApplicationInternalBehavior/GetEventStatus, operation=EvtInfo_Radar_System_Battery_High_Voltage_System_Voltage_High.GetEventStatus
        OpEventGetEventStatus_GetEventStatus_Event_Radar_System_Battery_High_Voltage_System_Voltage_High: start-on-event=DemSatellite_Invalid_OsApplicationInternalBehavior/GetEventStatus, operation=Event_Radar_System_Battery_High_Voltage_System_Voltage_High.GetEventStatus
        OpEventGetEventStatus_GetEventStatus_EvtInfo_CCVS1_message_Vehicle_Speed_Invalid_Serial_Data_Received: start-on-event=DemSatellite_Invalid_OsApplicationInternalBehavior/GetEventStatus, operation=EvtInfo_CCVS1_message_Vehicle_Speed_Invalid_Serial_Data_Received.GetEventStatus
        OpEventGetEventStatus_GetEventStatus_Event_CCVS1_message_Vehicle_Speed_Invalid_Serial_Data_Received: start-on-event=DemSatellite_Invalid_OsApplicationInternalBehavior/GetEventStatus, operation=Event_CCVS1_message_Vehicle_Speed_Invalid_Serial_Data_Received.GetEventStatus
        OpEventGetEventStatus_GetEventStatus_EvtInfo_EMS_ECU_VD_erratic_communication_Erratic: start-on-event=DemSatellite_Invalid_OsApplicationInternalBehavior/GetEventStatus, operation=EvtInfo_EMS_ECU_VD_erratic_communication_Erratic.GetEventStatus
        OpEventGetEventStatus_GetEventStatus_Event_EMS_ECU_VD_erratic_communication_Erratic: start-on-event=DemSatellite_Invalid_OsApplicationInternalBehavior/GetEventStatus, operation=Event_EMS_ECU_VD_erratic_communication_Erratic.GetEventStatus
        OpEventGetEventStatus_GetEventStatus_EvtInfo_EMS_ECU_ETC2_00_message_Missing_Message: start-on-event=DemSatellite_Invalid_OsApplicationInternalBehavior/GetEventStatus, operation=EvtInfo_EMS_ECU_ETC2_00_message_Missing_Message.GetEventStatus
        OpEventGetEventStatus_GetEventStatus_Event_EMS_ECU_ETC2_00_message_Missing_Message: start-on-event=DemSatellite_Invalid_OsApplicationInternalBehavior/GetEventStatus, operation=Event_EMS_ECU_ETC2_00_message_Missing_Message.GetEventStatus
        OpEventGetEventStatus_GetEventStatus_EvtInfo_Cluster_ECU_CLS_Tx_16_message_Missing_Message: start-on-event=DemSatellite_Invalid_OsApplicationInternalBehavior/GetEventStatus, operation=EvtInfo_Cluster_ECU_CLS_Tx_16_message_Missing_Message.GetEventStatus
        OpEventGetEventStatus_GetEventStatus_Event_Cluster_ECU_CLS_Tx_16_message_Missing_Message: start-on-event=DemSatellite_Invalid_OsApplicationInternalBehavior/GetEventStatus, operation=Event_Cluster_ECU_CLS_Tx_16_message_Missing_Message.GetEventStatus
        OpEventGetEventStatus_GetEventStatus_EvtInfo_Exceeded_Security_Access_0x27_Attempt_Threshold_Authentication_Failure: start-on-event=DemSatellite_Invalid_OsApplicationInternalBehavior/GetEventStatus, operation=EvtInfo_Exceeded_Security_Access_0x27_Attempt_Threshold_Authentication_Failure.GetEventStatus
        OpEventGetEventStatus_GetEventStatus_Event_Exceeded_Security_Access_0x27_Attempt_Threshold_Authentication_Failure: start-on-event=DemSatellite_Invalid_OsApplicationInternalBehavior/GetEventStatus, operation=Event_Exceeded_Security_Access_0x27_Attempt_Threshold_Authentication_Failure.GetEventStatus
        OpEventGetEventStatus_GetEventStatus_EvtInfo_Front_Left_Side_Radar_value_of_signal_protection_calculation_Incorrect: start-on-event=DemSatellite_Invalid_OsApplicationInternalBehavior/GetEventStatus, operation=EvtInfo_Front_Left_Side_Radar_value_of_signal_protection_calculation_Incorrect.GetEventStatus
        OpEventGetEventStatus_GetEventStatus_Event_Front_Left_Side_Radar_value_of_signal_protection_calculation_Incorrect: start-on-event=DemSatellite_Invalid_OsApplicationInternalBehavior/GetEventStatus, operation=Event_Front_Left_Side_Radar_value_of_signal_protection_calculation_Incorrect.GetEventStatus
        OpEventGetEventStatus_GetEventStatus_EvtInfo_AT_AMT_ETC2_erratic_communication_Erratic: start-on-event=DemSatellite_Invalid_OsApplicationInternalBehavior/GetEventStatus, operation=EvtInfo_AT_AMT_ETC2_erratic_communication_Erratic.GetEventStatus
        OpEventGetEventStatus_GetEventStatus_Event_AT_AMT_ETC2_erratic_communication_Erratic: start-on-event=DemSatellite_Invalid_OsApplicationInternalBehavior/GetEventStatus, operation=Event_AT_AMT_ETC2_erratic_communication_Erratic.GetEventStatus
        OpEventGetEventStatus_GetEventStatus_EvtInfo_VCAN_Communication_Bus_Off: start-on-event=DemSatellite_Invalid_OsApplicationInternalBehavior/GetEventStatus, operation=EvtInfo_VCAN_Communication_Bus_Off.GetEventStatus
        OpEventGetEventStatus_GetEventStatus_Event_VCAN_Communication_Bus_Off: start-on-event=DemSatellite_Invalid_OsApplicationInternalBehavior/GetEventStatus, operation=Event_VCAN_Communication_Bus_Off.GetEventStatus
        OpEventGetEventStatus_GetEventStatus_EvtInfo_VDC2_message_LongitudinalAcceleration_Invalid_Serial_Data_Received: start-on-event=DemSatellite_Invalid_OsApplicationInternalBehavior/GetEventStatus, operation=EvtInfo_VDC2_message_LongitudinalAcceleration_Invalid_Serial_Data_Received.GetEventStatus
        OpEventGetEventStatus_GetEventStatus_Event_VDC2_message_LongitudinalAcceleration_Invalid_Serial_Data_Received: start-on-event=DemSatellite_Invalid_OsApplicationInternalBehavior/GetEventStatus, operation=Event_VDC2_message_LongitudinalAcceleration_Invalid_Serial_Data_Received.GetEventStatus
        OpEventGetEventStatus_GetEventStatus_EvtInfo_Radar_MMIC_RFBIST_Component_Internal_Failure: start-on-event=DemSatellite_Invalid_OsApplicationInternalBehavior/GetEventStatus, operation=EvtInfo_Radar_MMIC_RFBIST_Component_Internal_Failure.GetEventStatus
        OpEventGetEventStatus_GetEventStatus_Event_Radar_MMIC_RFBIST_Component_Internal_Failure: start-on-event=DemSatellite_Invalid_OsApplicationInternalBehavior/GetEventStatus, operation=Event_Radar_MMIC_RFBIST_Component_Internal_Failure.GetEventStatus
        OpEventGetEventStatus_GetEventStatus_EvtInfo_Radar_Initial_Alignment_Missing_Calibration: start-on-event=DemSatellite_Invalid_OsApplicationInternalBehavior/GetEventStatus, operation=EvtInfo_Radar_Initial_Alignment_Missing_Calibration.GetEventStatus
        OpEventGetEventStatus_GetEventStatus_Event_Radar_Initial_Alignment_Missing_Calibration: start-on-event=DemSatellite_Invalid_OsApplicationInternalBehavior/GetEventStatus, operation=Event_Radar_Initial_Alignment_Missing_Calibration.GetEventStatus
        OpEventGetEventStatus_GetEventStatus_EvtInfo_Cluster_ECU_OEL_message_Missing_Message: start-on-event=DemSatellite_Invalid_OsApplicationInternalBehavior/GetEventStatus, operation=EvtInfo_Cluster_ECU_OEL_message_Missing_Message.GetEventStatus
        OpEventGetEventStatus_GetEventStatus_Event_Cluster_ECU_OEL_message_Missing_Message: start-on-event=DemSatellite_Invalid_OsApplicationInternalBehavior/GetEventStatus, operation=Event_Cluster_ECU_OEL_message_Missing_Message.GetEventStatus
        OpEventGetEventStatus_GetEventStatus_EvtInfo_AT_AMT_ECU_ETC2_03_message_Missing_Message: start-on-event=DemSatellite_Invalid_OsApplicationInternalBehavior/GetEventStatus, operation=EvtInfo_AT_AMT_ECU_ETC2_03_message_Missing_Message.GetEventStatus
        OpEventGetEventStatus_GetEventStatus_Event_AT_AMT_ECU_ETC2_03_message_Missing_Message: start-on-event=DemSatellite_Invalid_OsApplicationInternalBehavior/GetEventStatus, operation=Event_AT_AMT_ECU_ETC2_03_message_Missing_Message.GetEventStatus
        OpEventGetEventStatus_GetEventStatus_EvtInfo_ADAS_FN_STS_message_MOIS_FN_Switch_STS_Invalid_Serial_Data_Received: start-on-event=DemSatellite_Invalid_OsApplicationInternalBehavior/GetEventStatus, operation=EvtInfo_ADAS_FN_STS_message_MOIS_FN_Switch_STS_Invalid_Serial_Data_Received.GetEventStatus
        OpEventGetEventStatus_GetEventStatus_Event_ADAS_FN_STS_message_MOIS_FN_Switch_STS_Invalid_Serial_Data_Received: start-on-event=DemSatellite_Invalid_OsApplicationInternalBehavior/GetEventStatus, operation=Event_ADAS_FN_STS_message_MOIS_FN_Switch_STS_Invalid_Serial_Data_Received.GetEventStatus
        OpEventGetEventStatus_GetEventStatus_EvtInfo_Radar_Module_Over_Temperature: start-on-event=DemSatellite_Invalid_OsApplicationInternalBehavior/GetEventStatus, operation=EvtInfo_Radar_Module_Over_Temperature.GetEventStatus
        OpEventGetEventStatus_GetEventStatus_Event_Radar_Module_Over_Temperature: start-on-event=DemSatellite_Invalid_OsApplicationInternalBehavior/GetEventStatus, operation=Event_Radar_Module_Over_Temperature.GetEventStatus
        OpEventGetEventStatus_GetEventStatus_EvtInfo_PCAN_TimeSync_Missing_Message: start-on-event=DemSatellite_Invalid_OsApplicationInternalBehavior/GetEventStatus, operation=EvtInfo_PCAN_TimeSync_Missing_Message.GetEventStatus
        OpEventGetEventStatus_GetEventStatus_Event_PCAN_TimeSync_Missing_Message: start-on-event=DemSatellite_Invalid_OsApplicationInternalBehavior/GetEventStatus, operation=Event_PCAN_TimeSync_Missing_Message.GetEventStatus
        OpEventGetEventStatus_GetEventStatus_EvtInfo_Radar_Module_Watchdog_Failure: start-on-event=DemSatellite_Invalid_OsApplicationInternalBehavior/GetEventStatus, operation=EvtInfo_Radar_Module_Watchdog_Failure.GetEventStatus
        OpEventGetEventStatus_GetEventStatus_Event_Radar_Module_Watchdog_Failure: start-on-event=DemSatellite_Invalid_OsApplicationInternalBehavior/GetEventStatus, operation=Event_Radar_Module_Watchdog_Failure.GetEventStatus
        OpEventGetEventStatus_GetEventStatus_EvtInfo_SAS_ECU_SAS_message_Missing_Message: start-on-event=DemSatellite_Invalid_OsApplicationInternalBehavior/GetEventStatus, operation=EvtInfo_SAS_ECU_SAS_message_Missing_Message.GetEventStatus
        OpEventGetEventStatus_GetEventStatus_Event_SAS_ECU_SAS_message_Missing_Message: start-on-event=DemSatellite_Invalid_OsApplicationInternalBehavior/GetEventStatus, operation=Event_SAS_ECU_SAS_message_Missing_Message.GetEventStatus
        OpEventGetEventStatus_GetEventStatus_EvtInfo_ECU_NVM_Corruption_Program_memory_Failure: start-on-event=DemSatellite_Invalid_OsApplicationInternalBehavior/GetEventStatus, operation=EvtInfo_ECU_NVM_Corruption_Program_memory_Failure.GetEventStatus
        OpEventGetEventStatus_GetEventStatus_Event_ECU_NVM_Corruption_Program_memory_Failure: start-on-event=DemSatellite_Invalid_OsApplicationInternalBehavior/GetEventStatus, operation=Event_ECU_NVM_Corruption_Program_memory_Failure.GetEventStatus
        OpEventGetEventStatus_GetEventStatus_EvtInfo_Cluster_ECU_TD_message_Missing_Message: start-on-event=DemSatellite_Invalid_OsApplicationInternalBehavior/GetEventStatus, operation=EvtInfo_Cluster_ECU_TD_message_Missing_Message.GetEventStatus
        OpEventGetEventStatus_GetEventStatus_Event_Cluster_ECU_TD_message_Missing_Message: start-on-event=DemSatellite_Invalid_OsApplicationInternalBehavior/GetEventStatus, operation=Event_Cluster_ECU_TD_message_Missing_Message.GetEventStatus
        OpEventGetEventStatus_GetEventStatus_EvtInfo_PCAN_Communication_Bus_Off: start-on-event=DemSatellite_Invalid_OsApplicationInternalBehavior/GetEventStatus, operation=EvtInfo_PCAN_Communication_Bus_Off.GetEventStatus
        OpEventGetEventStatus_GetEventStatus_Event_PCAN_Communication_Bus_Off: start-on-event=DemSatellite_Invalid_OsApplicationInternalBehavior/GetEventStatus, operation=Event_PCAN_Communication_Bus_Off.GetEventStatus
        OpEventGetEventStatus_GetEventStatus_EvtInfo_Front_Left_Side_Radar_Missing_Message: start-on-event=DemSatellite_Invalid_OsApplicationInternalBehavior/GetEventStatus, operation=EvtInfo_Front_Left_Side_Radar_Missing_Message.GetEventStatus
        OpEventGetEventStatus_GetEventStatus_Event_Front_Left_Side_Radar_Missing_Message: start-on-event=DemSatellite_Invalid_OsApplicationInternalBehavior/GetEventStatus, operation=Event_Front_Left_Side_Radar_Missing_Message.GetEventStatus
        OpEventGetEventStatus_GetEventStatus_EvtInfo_Manual_ETC2_message_Transcurrent_gear_Invalid_Serial_Data_Received: start-on-event=DemSatellite_Invalid_OsApplicationInternalBehavior/GetEventStatus, operation=EvtInfo_Manual_ETC2_message_Transcurrent_gear_Invalid_Serial_Data_Received.GetEventStatus
        OpEventGetEventStatus_GetEventStatus_Event_Manual_ETC2_message_Transcurrent_gear_Invalid_Serial_Data_Received: start-on-event=DemSatellite_Invalid_OsApplicationInternalBehavior/GetEventStatus, operation=Event_Manual_ETC2_message_Transcurrent_gear_Invalid_Serial_Data_Received.GetEventStatus
        OpEventGetEventStatus_GetEventStatus_EvtInfo_SAS_ECU_erratic_communication_Erratic: start-on-event=DemSatellite_Invalid_OsApplicationInternalBehavior/GetEventStatus, operation=EvtInfo_SAS_ECU_erratic_communication_Erratic.GetEventStatus
        OpEventGetEventStatus_GetEventStatus_Event_SAS_ECU_erratic_communication_Erratic: start-on-event=DemSatellite_Invalid_OsApplicationInternalBehavior/GetEventStatus, operation=Event_SAS_ECU_erratic_communication_Erratic.GetEventStatus
        OpEventGetEventStatus_GetEventStatus_EvtInfo_VDC2_message_Yaw_rate_Invalid_Serial_Data_Received: start-on-event=DemSatellite_Invalid_OsApplicationInternalBehavior/GetEventStatus, operation=EvtInfo_VDC2_message_Yaw_rate_Invalid_Serial_Data_Received.GetEventStatus
        OpEventGetEventStatus_GetEventStatus_Event_VDC2_message_Yaw_rate_Invalid_Serial_Data_Received: start-on-event=DemSatellite_Invalid_OsApplicationInternalBehavior/GetEventStatus, operation=Event_VDC2_message_Yaw_rate_Invalid_Serial_Data_Received.GetEventStatus
        OpEventGetEventStatus_GetEventStatus_EvtInfo_Cluster_ECU_TD_erratic_communication_Erratic: start-on-event=DemSatellite_Invalid_OsApplicationInternalBehavior/GetEventStatus, operation=EvtInfo_Cluster_ECU_TD_erratic_communication_Erratic.GetEventStatus
        OpEventGetEventStatus_GetEventStatus_Event_Cluster_ECU_TD_erratic_communication_Erratic: start-on-event=DemSatellite_Invalid_OsApplicationInternalBehavior/GetEventStatus, operation=Event_Cluster_ECU_TD_erratic_communication_Erratic.GetEventStatus
        OpEventGetEventStatus_GetEventStatus_EvtInfo_EMS_ECU_CCVS1_message_Missing_Message: start-on-event=DemSatellite_Invalid_OsApplicationInternalBehavior/GetEventStatus, operation=EvtInfo_EMS_ECU_CCVS1_message_Missing_Message.GetEventStatus
        OpEventGetEventStatus_GetEventStatus_Event_EMS_ECU_CCVS1_message_Missing_Message: start-on-event=DemSatellite_Invalid_OsApplicationInternalBehavior/GetEventStatus, operation=Event_EMS_ECU_CCVS1_message_Missing_Message.GetEventStatus
        OpEventGetEventStatus_GetEventStatus_EvtInfo_Radar_Mounting_Orientation_Incorrect_Assembly: start-on-event=DemSatellite_Invalid_OsApplicationInternalBehavior/GetEventStatus, operation=EvtInfo_Radar_Mounting_Orientation_Incorrect_Assembly.GetEventStatus
        OpEventGetEventStatus_GetEventStatus_Event_Radar_Mounting_Orientation_Incorrect_Assembly: start-on-event=DemSatellite_Invalid_OsApplicationInternalBehavior/GetEventStatus, operation=Event_Radar_Mounting_Orientation_Incorrect_Assembly.GetEventStatus
        OpEventGetEventStatus_GetEventStatus_EvtInfo_EMS_ECU_ETC2_erratic_communication_Erractic: start-on-event=DemSatellite_Invalid_OsApplicationInternalBehavior/GetEventStatus, operation=EvtInfo_EMS_ECU_ETC2_erratic_communication_Erractic.GetEventStatus
        OpEventGetEventStatus_GetEventStatus_Event_EMS_ECU_ETC2_erratic_communication_Erractic: start-on-event=DemSatellite_Invalid_OsApplicationInternalBehavior/GetEventStatus, operation=Event_EMS_ECU_ETC2_erratic_communication_Erractic.GetEventStatus
        OpEventGetEventStatus_GetEventStatus_EvtInfo_Cluster_ECU_ADAS_FN_STS_erratic_communication_Erratic: start-on-event=DemSatellite_Invalid_OsApplicationInternalBehavior/GetEventStatus, operation=EvtInfo_Cluster_ECU_ADAS_FN_STS_erratic_communication_Erratic.GetEventStatus
        OpEventGetEventStatus_GetEventStatus_Event_Cluster_ECU_ADAS_FN_STS_erratic_communication_Erratic: start-on-event=DemSatellite_Invalid_OsApplicationInternalBehavior/GetEventStatus, operation=Event_Cluster_ECU_ADAS_FN_STS_erratic_communication_Erratic.GetEventStatus
        OpEventGetEventStatus_GetEventStatus_EvtInfo_ESC_ECU_VDC2_message_Missing_Message: start-on-event=DemSatellite_Invalid_OsApplicationInternalBehavior/GetEventStatus, operation=EvtInfo_ESC_ECU_VDC2_message_Missing_Message.GetEventStatus
        OpEventGetEventStatus_GetEventStatus_Event_ESC_ECU_VDC2_message_Missing_Message: start-on-event=DemSatellite_Invalid_OsApplicationInternalBehavior/GetEventStatus, operation=Event_ESC_ECU_VDC2_message_Missing_Message.GetEventStatus
        OpEventGetEventStatus_GetEventStatus_EvtInfo_CLS_TX_16_message_Transmission_Type_info_Invalid_Serial_Data_Received: start-on-event=DemSatellite_Invalid_OsApplicationInternalBehavior/GetEventStatus, operation=EvtInfo_CLS_TX_16_message_Transmission_Type_info_Invalid_Serial_Data_Received.GetEventStatus
        OpEventGetEventStatus_GetEventStatus_Event_CLS_TX_16_message_Transmission_Type_info_Invalid_Serial_Data_Received: start-on-event=DemSatellite_Invalid_OsApplicationInternalBehavior/GetEventStatus, operation=Event_CLS_TX_16_message_Transmission_Type_info_Invalid_Serial_Data_Received.GetEventStatus
        OpEventGetEventStatus_GetEventStatus_EvtInfo_Cluster_ECU_CLS_Tx_4_erratic_communication_Erratic: start-on-event=DemSatellite_Invalid_OsApplicationInternalBehavior/GetEventStatus, operation=EvtInfo_Cluster_ECU_CLS_Tx_4_erratic_communication_Erratic.GetEventStatus
        OpEventGetEventStatus_GetEventStatus_Event_Cluster_ECU_CLS_Tx_4_erratic_communication_Erratic: start-on-event=DemSatellite_Invalid_OsApplicationInternalBehavior/GetEventStatus, operation=Event_Cluster_ECU_CLS_Tx_4_erratic_communication_Erratic.GetEventStatus
        OpEventGetEventStatus_GetEventStatus_EvtInfo_Cluster_ECU_ADAS_FN_STS_message_Missing_Message: start-on-event=DemSatellite_Invalid_OsApplicationInternalBehavior/GetEventStatus, operation=EvtInfo_Cluster_ECU_ADAS_FN_STS_message_Missing_Message.GetEventStatus
        OpEventGetEventStatus_GetEventStatus_Event_Cluster_ECU_ADAS_FN_STS_message_Missing_Message: start-on-event=DemSatellite_Invalid_OsApplicationInternalBehavior/GetEventStatus, operation=Event_Cluster_ECU_ADAS_FN_STS_message_Missing_Message.GetEventStatus
        OpEventGetEventStatus_GetEventStatus_EvtInfo_Vehicle_Dataset_value_of_signal_protection_calculation_Incorrect: start-on-event=DemSatellite_Invalid_OsApplicationInternalBehavior/GetEventStatus, operation=EvtInfo_Vehicle_Dataset_value_of_signal_protection_calculation_Incorrect.GetEventStatus
        OpEventGetEventStatus_GetEventStatus_Event_Vehicle_Dataset_value_of_signal_protection_calculation_Incorrect: start-on-event=DemSatellite_Invalid_OsApplicationInternalBehavior/GetEventStatus, operation=Event_Vehicle_Dataset_value_of_signal_protection_calculation_Incorrect.GetEventStatus
        OpEventGetEventStatus_GetEventStatus_EvtInfo_Cluster_ECU_CLS_Tx_16_erratic_communication_Erratic: start-on-event=DemSatellite_Invalid_OsApplicationInternalBehavior/GetEventStatus, operation=EvtInfo_Cluster_ECU_CLS_Tx_16_erratic_communication_Erratic.GetEventStatus
        OpEventGetEventStatus_GetEventStatus_Event_Cluster_ECU_CLS_Tx_16_erratic_communication_Erratic: start-on-event=DemSatellite_Invalid_OsApplicationInternalBehavior/GetEventStatus, operation=Event_Cluster_ECU_CLS_Tx_16_erratic_communication_Erratic.GetEventStatus
        OpEventGetEventStatus_GetEventStatus_EvtInfo_Cluster_ECU_OEL_erratic_communication_Erratic: start-on-event=DemSatellite_Invalid_OsApplicationInternalBehavior/GetEventStatus, operation=EvtInfo_Cluster_ECU_OEL_erratic_communication_Erratic.GetEventStatus
        OpEventGetEventStatus_GetEventStatus_Event_Cluster_ECU_OEL_erratic_communication_Erratic: start-on-event=DemSatellite_Invalid_OsApplicationInternalBehavior/GetEventStatus, operation=Event_Cluster_ECU_OEL_erratic_communication_Erratic.GetEventStatus
        OpEventGetEventStatus_GetEventStatus_EvtInfo_Cluster_ECU_CLS_Tx_4_message_Missing_Message: start-on-event=DemSatellite_Invalid_OsApplicationInternalBehavior/GetEventStatus, operation=EvtInfo_Cluster_ECU_CLS_Tx_4_message_Missing_Message.GetEventStatus
        OpEventGetEventStatus_GetEventStatus_Event_Cluster_ECU_CLS_Tx_4_message_Missing_Message: start-on-event=DemSatellite_Invalid_OsApplicationInternalBehavior/GetEventStatus, operation=Event_Cluster_ECU_CLS_Tx_4_message_Missing_Message.GetEventStatus
        OpEventGetEventStatus_GetEventStatus_EvtInfo_Radar_Performance_Capability_Algorithm_Based_Failure: start-on-event=DemSatellite_Invalid_OsApplicationInternalBehavior/GetEventStatus, operation=EvtInfo_Radar_Performance_Capability_Algorithm_Based_Failure.GetEventStatus
        OpEventGetEventStatus_GetEventStatus_Event_Radar_Performance_Capability_Algorithm_Based_Failure: start-on-event=DemSatellite_Invalid_OsApplicationInternalBehavior/GetEventStatus, operation=Event_Radar_Performance_Capability_Algorithm_Based_Failure.GetEventStatus
        OpEventGetEventStatus_GetEventStatus_EvtInfo_Radar_AutoAlignment_Range_Alignment_or_Adjustement_Incorrect: start-on-event=DemSatellite_Invalid_OsApplicationInternalBehavior/GetEventStatus, operation=EvtInfo_Radar_AutoAlignment_Range_Alignment_or_Adjustement_Incorrect.GetEventStatus
        OpEventGetEventStatus_GetEventStatus_Event_Radar_AutoAlignment_Range_Alignment_or_Adjustement_Incorrect: start-on-event=DemSatellite_Invalid_OsApplicationInternalBehavior/GetEventStatus, operation=Event_Radar_AutoAlignment_Range_Alignment_or_Adjustement_Incorrect.GetEventStatus
        OpEventGetEventStatus_GetEventStatus_EvtInfo_EMS_ECU_CCVS1_erratic_communication_Erractic: start-on-event=DemSatellite_Invalid_OsApplicationInternalBehavior/GetEventStatus, operation=EvtInfo_EMS_ECU_CCVS1_erratic_communication_Erractic.GetEventStatus
        OpEventGetEventStatus_GetEventStatus_Event_EMS_ECU_CCVS1_erratic_communication_Erractic: start-on-event=DemSatellite_Invalid_OsApplicationInternalBehavior/GetEventStatus, operation=Event_EMS_ECU_CCVS1_erratic_communication_Erractic.GetEventStatus
        OpEventGetEventStatus_GetEventStatus_EvtInfo_Radar_System_Battery_Low_Voltage_System_Voltage_Low: start-on-event=DemSatellite_Invalid_OsApplicationInternalBehavior/GetEventStatus, operation=EvtInfo_Radar_System_Battery_Low_Voltage_System_Voltage_Low.GetEventStatus
        OpEventGetEventStatus_GetEventStatus_Event_Radar_System_Battery_Low_Voltage_System_Voltage_Low: start-on-event=DemSatellite_Invalid_OsApplicationInternalBehavior/GetEventStatus, operation=Event_Radar_System_Battery_Low_Voltage_System_Voltage_Low.GetEventStatus
        OpEventGetEventStatus_GetEventStatus_EvtInfo_Radar_SMC_General_Checksum_Failure: start-on-event=DemSatellite_Invalid_OsApplicationInternalBehavior/GetEventStatus, operation=EvtInfo_Radar_SMC_General_Checksum_Failure.GetEventStatus
        OpEventGetEventStatus_GetEventStatus_Event_Radar_SMC_General_Checksum_Failure: start-on-event=DemSatellite_Invalid_OsApplicationInternalBehavior/GetEventStatus, operation=Event_Radar_SMC_General_Checksum_Failure.GetEventStatus
        OpEventGetEventStatus_GetEventStatus_EvtInfo_Radar_Pin_Position_Wrong_Mounting_Position: start-on-event=DemSatellite_Invalid_OsApplicationInternalBehavior/GetEventStatus, operation=EvtInfo_Radar_Pin_Position_Wrong_Mounting_Position.GetEventStatus
        OpEventGetEventStatus_GetEventStatus_Event_Radar_Pin_Position_Wrong_Mounting_Position: start-on-event=DemSatellite_Invalid_OsApplicationInternalBehavior/GetEventStatus, operation=Event_Radar_Pin_Position_Wrong_Mounting_Position.GetEventStatus
        OpEventGetEventStatus_GetEventStatus_EvtInfo_VDC2_message_Lateral_Accleration_Invalid_Serial_Data_Received: start-on-event=DemSatellite_Invalid_OsApplicationInternalBehavior/GetEventStatus, operation=EvtInfo_VDC2_message_Lateral_Accleration_Invalid_Serial_Data_Received.GetEventStatus
        OpEventGetEventStatus_GetEventStatus_Event_VDC2_message_Lateral_Accleration_Invalid_Serial_Data_Received: start-on-event=DemSatellite_Invalid_OsApplicationInternalBehavior/GetEventStatus, operation=Event_VDC2_message_Lateral_Accleration_Invalid_Serial_Data_Received.GetEventStatus
        OpEventGetEventStatus_GetEventStatus_EvtInfo_ADAS_FN_STS_message_BSIS_FN_Switch_STS_Invalid_Serial_Data_Received: start-on-event=DemSatellite_Invalid_OsApplicationInternalBehavior/GetEventStatus, operation=EvtInfo_ADAS_FN_STS_message_BSIS_FN_Switch_STS_Invalid_Serial_Data_Received.GetEventStatus
        OpEventGetEventStatus_GetEventStatus_Event_ADAS_FN_STS_message_BSIS_FN_Switch_STS_Invalid_Serial_Data_Received: start-on-event=DemSatellite_Invalid_OsApplicationInternalBehavior/GetEventStatus, operation=Event_ADAS_FN_STS_message_BSIS_FN_Switch_STS_Invalid_Serial_Data_Received.GetEventStatus
        OpEventGetEventStatus_GetEventStatus_EvtInfo_Radar_AutoAlignment_Misalignment_Performance_or_Incorrect_Operation: start-on-event=DemSatellite_Invalid_OsApplicationInternalBehavior/GetEventStatus, operation=EvtInfo_Radar_AutoAlignment_Misalignment_Performance_or_Incorrect_Operation.GetEventStatus
        OpEventGetEventStatus_GetEventStatus_Event_Radar_AutoAlignment_Misalignment_Performance_or_Incorrect_Operation: start-on-event=DemSatellite_Invalid_OsApplicationInternalBehavior/GetEventStatus, operation=Event_Radar_AutoAlignment_Misalignment_Performance_or_Incorrect_Operation.GetEventStatus
        OpEventGetEventStatus_GetEventStatus_EvtInfo_ESC_ECU_VDC2_erratic_communication_Erratic: start-on-event=DemSatellite_Invalid_OsApplicationInternalBehavior/GetEventStatus, operation=EvtInfo_ESC_ECU_VDC2_erratic_communication_Erratic.GetEventStatus
        OpEventGetEventStatus_GetEventStatus_Event_ESC_ECU_VDC2_erratic_communication_Erratic: start-on-event=DemSatellite_Invalid_OsApplicationInternalBehavior/GetEventStatus, operation=Event_ESC_ECU_VDC2_erratic_communication_Erratic.GetEventStatus
        OpEventGetEventStatus_GetEventStatus_EvtInfo_Application_Interface_Lookup_Performance_or_Incorrect_Operation: start-on-event=DemSatellite_Invalid_OsApplicationInternalBehavior/GetEventStatus, operation=EvtInfo_Application_Interface_Lookup_Performance_or_Incorrect_Operation.GetEventStatus
        OpEventGetEventStatus_GetEventStatus_Event_Application_Interface_Lookup_Performance_or_Incorrect_Operation: start-on-event=DemSatellite_Invalid_OsApplicationInternalBehavior/GetEventStatus, operation=Event_Application_Interface_Lookup_Performance_or_Incorrect_Operation.GetEventStatus
        OpEventGetEventStatus_GetEventStatus_EvtInfo_EMS_ECU_VD_message_Missing_Message: start-on-event=DemSatellite_Invalid_OsApplicationInternalBehavior/GetEventStatus, operation=EvtInfo_EMS_ECU_VD_message_Missing_Message.GetEventStatus
        OpEventGetEventStatus_GetEventStatus_Event_EMS_ECU_VD_message_Missing_Message: start-on-event=DemSatellite_Invalid_OsApplicationInternalBehavior/GetEventStatus, operation=Event_EMS_ECU_VD_message_Missing_Message.GetEventStatus
        OpEventGetEventStatus_GetEventStatus_EvtInfo_Radar_Platform_Time_System_Programming_Failure: start-on-event=DemSatellite_Invalid_OsApplicationInternalBehavior/GetEventStatus, operation=EvtInfo_Radar_Platform_Time_System_Programming_Failure.GetEventStatus
        OpEventGetEventStatus_GetEventStatus_Event_Radar_Platform_Time_System_Programming_Failure: start-on-event=DemSatellite_Invalid_OsApplicationInternalBehavior/GetEventStatus, operation=Event_Radar_Platform_Time_System_Programming_Failure.GetEventStatus
        OpEventGetEventStatus_GetEventStatus_EvtInfo_OEL_message_Turn_Signal_Switch_Invalid_Serial_Data_Received: start-on-event=DemSatellite_Invalid_OsApplicationInternalBehavior/GetEventStatus, operation=EvtInfo_OEL_message_Turn_Signal_Switch_Invalid_Serial_Data_Received.GetEventStatus
        OpEventGetEventStatus_GetEventStatus_Event_OEL_message_Turn_Signal_Switch_Invalid_Serial_Data_Received: start-on-event=DemSatellite_Invalid_OsApplicationInternalBehavior/GetEventStatus, operation=Event_OEL_message_Turn_Signal_Switch_Invalid_Serial_Data_Received.GetEventStatus
        OpEventGetEventStatus_GetEventStatus_EvtInfo_Radar_calibration_Calibration_or_Paramater_Memory_Failure: start-on-event=DemSatellite_Invalid_OsApplicationInternalBehavior/GetEventStatus, operation=EvtInfo_Radar_calibration_Calibration_or_Paramater_Memory_Failure.GetEventStatus
        OpEventGetEventStatus_GetEventStatus_Event_Radar_calibration_Calibration_or_Paramater_Memory_Failure: start-on-event=DemSatellite_Invalid_OsApplicationInternalBehavior/GetEventStatus, operation=Event_Radar_calibration_Calibration_or_Paramater_Memory_Failure.GetEventStatus
        OpEventGetEventStatus_GetEventStatus_GeneralEvtInfo: start-on-event=DemSatellite_Invalid_OsApplicationInternalBehavior/GetEventStatus, operation=GeneralEvtInfo.GetEventStatus
        OpEventGetEventFailed_GetEventFailed_EvtInfo_SAS_message_Steering_Wheel_Angle_Invalid_Serial_Data_Received: start-on-event=DemSatellite_Invalid_OsApplicationInternalBehavior/GetEventFailed, operation=EvtInfo_SAS_message_Steering_Wheel_Angle_Invalid_Serial_Data_Received.GetEventFailed
        OpEventGetEventFailed_GetEventFailed_Event_SAS_message_Steering_Wheel_Angle_Invalid_Serial_Data_Received: start-on-event=DemSatellite_Invalid_OsApplicationInternalBehavior/GetEventFailed, operation=Event_SAS_message_Steering_Wheel_Angle_Invalid_Serial_Data_Received.GetEventFailed
        OpEventGetEventFailed_GetEventFailed_EvtInfo_AT_AMT_ETC2_message_Transcurrent_gear_Invalid_Serial_Data_Received: start-on-event=DemSatellite_Invalid_OsApplicationInternalBehavior/GetEventFailed, operation=EvtInfo_AT_AMT_ETC2_message_Transcurrent_gear_Invalid_Serial_Data_Received.GetEventFailed
        OpEventGetEventFailed_GetEventFailed_Event_AT_AMT_ETC2_message_Transcurrent_gear_Invalid_Serial_Data_Received: start-on-event=DemSatellite_Invalid_OsApplicationInternalBehavior/GetEventFailed, operation=Event_AT_AMT_ETC2_message_Transcurrent_gear_Invalid_Serial_Data_Received.GetEventFailed
        OpEventGetEventFailed_GetEventFailed_EvtInfo_Radar_AutoAlignment_Algorithm_Signal_Calculation_Failure: start-on-event=DemSatellite_Invalid_OsApplicationInternalBehavior/GetEventFailed, operation=EvtInfo_Radar_AutoAlignment_Algorithm_Signal_Calculation_Failure.GetEventFailed
        OpEventGetEventFailed_GetEventFailed_Event_Radar_AutoAlignment_Algorithm_Signal_Calculation_Failure: start-on-event=DemSatellite_Invalid_OsApplicationInternalBehavior/GetEventFailed, operation=Event_Radar_AutoAlignment_Algorithm_Signal_Calculation_Failure.GetEventFailed
        OpEventGetEventFailed_GetEventFailed_EvtInfo_Vehicle_DataSet_Not_Configured: start-on-event=DemSatellite_Invalid_OsApplicationInternalBehavior/GetEventFailed, operation=EvtInfo_Vehicle_DataSet_Not_Configured.GetEventFailed
        OpEventGetEventFailed_GetEventFailed_Event_Vehicle_DataSet_Not_Configured: start-on-event=DemSatellite_Invalid_OsApplicationInternalBehavior/GetEventFailed, operation=Event_Vehicle_DataSet_Not_Configured.GetEventFailed
        OpEventGetEventFailed_GetEventFailed_EvtInfo_Radar_Module_System_Internal_Failure: start-on-event=DemSatellite_Invalid_OsApplicationInternalBehavior/GetEventFailed, operation=EvtInfo_Radar_Module_System_Internal_Failure.GetEventFailed
        OpEventGetEventFailed_GetEventFailed_Event_Radar_Module_System_Internal_Failure: start-on-event=DemSatellite_Invalid_OsApplicationInternalBehavior/GetEventFailed, operation=Event_Radar_Module_System_Internal_Failure.GetEventFailed
        OpEventGetEventFailed_GetEventFailed_EvtInfo_Radar_MMIC_Component_Failure: start-on-event=DemSatellite_Invalid_OsApplicationInternalBehavior/GetEventFailed, operation=EvtInfo_Radar_MMIC_Component_Failure.GetEventFailed
        OpEventGetEventFailed_GetEventFailed_Event_Radar_MMIC_Component_Failure: start-on-event=DemSatellite_Invalid_OsApplicationInternalBehavior/GetEventFailed, operation=Event_Radar_MMIC_Component_Failure.GetEventFailed
        OpEventGetEventFailed_GetEventFailed_EvtInfo_Radar_Module_General_Memory_Failure: start-on-event=DemSatellite_Invalid_OsApplicationInternalBehavior/GetEventFailed, operation=EvtInfo_Radar_Module_General_Memory_Failure.GetEventFailed
        OpEventGetEventFailed_GetEventFailed_Event_Radar_Module_General_Memory_Failure: start-on-event=DemSatellite_Invalid_OsApplicationInternalBehavior/GetEventFailed, operation=Event_Radar_Module_General_Memory_Failure.GetEventFailed
        OpEventGetEventFailed_GetEventFailed_EvtInfo_Radar_System_Battery_High_Voltage_System_Voltage_High: start-on-event=DemSatellite_Invalid_OsApplicationInternalBehavior/GetEventFailed, operation=EvtInfo_Radar_System_Battery_High_Voltage_System_Voltage_High.GetEventFailed
        OpEventGetEventFailed_GetEventFailed_Event_Radar_System_Battery_High_Voltage_System_Voltage_High: start-on-event=DemSatellite_Invalid_OsApplicationInternalBehavior/GetEventFailed, operation=Event_Radar_System_Battery_High_Voltage_System_Voltage_High.GetEventFailed
        OpEventGetEventFailed_GetEventFailed_EvtInfo_CCVS1_message_Vehicle_Speed_Invalid_Serial_Data_Received: start-on-event=DemSatellite_Invalid_OsApplicationInternalBehavior/GetEventFailed, operation=EvtInfo_CCVS1_message_Vehicle_Speed_Invalid_Serial_Data_Received.GetEventFailed
        OpEventGetEventFailed_GetEventFailed_Event_CCVS1_message_Vehicle_Speed_Invalid_Serial_Data_Received: start-on-event=DemSatellite_Invalid_OsApplicationInternalBehavior/GetEventFailed, operation=Event_CCVS1_message_Vehicle_Speed_Invalid_Serial_Data_Received.GetEventFailed
        OpEventGetEventFailed_GetEventFailed_EvtInfo_EMS_ECU_VD_erratic_communication_Erratic: start-on-event=DemSatellite_Invalid_OsApplicationInternalBehavior/GetEventFailed, operation=EvtInfo_EMS_ECU_VD_erratic_communication_Erratic.GetEventFailed
        OpEventGetEventFailed_GetEventFailed_Event_EMS_ECU_VD_erratic_communication_Erratic: start-on-event=DemSatellite_Invalid_OsApplicationInternalBehavior/GetEventFailed, operation=Event_EMS_ECU_VD_erratic_communication_Erratic.GetEventFailed
        OpEventGetEventFailed_GetEventFailed_EvtInfo_EMS_ECU_ETC2_00_message_Missing_Message: start-on-event=DemSatellite_Invalid_OsApplicationInternalBehavior/GetEventFailed, operation=EvtInfo_EMS_ECU_ETC2_00_message_Missing_Message.GetEventFailed
        OpEventGetEventFailed_GetEventFailed_Event_EMS_ECU_ETC2_00_message_Missing_Message: start-on-event=DemSatellite_Invalid_OsApplicationInternalBehavior/GetEventFailed, operation=Event_EMS_ECU_ETC2_00_message_Missing_Message.GetEventFailed
        OpEventGetEventFailed_GetEventFailed_EvtInfo_Cluster_ECU_CLS_Tx_16_message_Missing_Message: start-on-event=DemSatellite_Invalid_OsApplicationInternalBehavior/GetEventFailed, operation=EvtInfo_Cluster_ECU_CLS_Tx_16_message_Missing_Message.GetEventFailed
        OpEventGetEventFailed_GetEventFailed_Event_Cluster_ECU_CLS_Tx_16_message_Missing_Message: start-on-event=DemSatellite_Invalid_OsApplicationInternalBehavior/GetEventFailed, operation=Event_Cluster_ECU_CLS_Tx_16_message_Missing_Message.GetEventFailed
        OpEventGetEventFailed_GetEventFailed_EvtInfo_Exceeded_Security_Access_0x27_Attempt_Threshold_Authentication_Failure: start-on-event=DemSatellite_Invalid_OsApplicationInternalBehavior/GetEventFailed, operation=EvtInfo_Exceeded_Security_Access_0x27_Attempt_Threshold_Authentication_Failure.GetEventFailed
        OpEventGetEventFailed_GetEventFailed_Event_Exceeded_Security_Access_0x27_Attempt_Threshold_Authentication_Failure: start-on-event=DemSatellite_Invalid_OsApplicationInternalBehavior/GetEventFailed, operation=Event_Exceeded_Security_Access_0x27_Attempt_Threshold_Authentication_Failure.GetEventFailed
        OpEventGetEventFailed_GetEventFailed_EvtInfo_Front_Left_Side_Radar_value_of_signal_protection_calculation_Incorrect: start-on-event=DemSatellite_Invalid_OsApplicationInternalBehavior/GetEventFailed, operation=EvtInfo_Front_Left_Side_Radar_value_of_signal_protection_calculation_Incorrect.GetEventFailed
        OpEventGetEventFailed_GetEventFailed_Event_Front_Left_Side_Radar_value_of_signal_protection_calculation_Incorrect: start-on-event=DemSatellite_Invalid_OsApplicationInternalBehavior/GetEventFailed, operation=Event_Front_Left_Side_Radar_value_of_signal_protection_calculation_Incorrect.GetEventFailed
        OpEventGetEventFailed_GetEventFailed_EvtInfo_AT_AMT_ETC2_erratic_communication_Erratic: start-on-event=DemSatellite_Invalid_OsApplicationInternalBehavior/GetEventFailed, operation=EvtInfo_AT_AMT_ETC2_erratic_communication_Erratic.GetEventFailed
        OpEventGetEventFailed_GetEventFailed_Event_AT_AMT_ETC2_erratic_communication_Erratic: start-on-event=DemSatellite_Invalid_OsApplicationInternalBehavior/GetEventFailed, operation=Event_AT_AMT_ETC2_erratic_communication_Erratic.GetEventFailed
        OpEventGetEventFailed_GetEventFailed_EvtInfo_VCAN_Communication_Bus_Off: start-on-event=DemSatellite_Invalid_OsApplicationInternalBehavior/GetEventFailed, operation=EvtInfo_VCAN_Communication_Bus_Off.GetEventFailed
        OpEventGetEventFailed_GetEventFailed_Event_VCAN_Communication_Bus_Off: start-on-event=DemSatellite_Invalid_OsApplicationInternalBehavior/GetEventFailed, operation=Event_VCAN_Communication_Bus_Off.GetEventFailed
        OpEventGetEventFailed_GetEventFailed_EvtInfo_VDC2_message_LongitudinalAcceleration_Invalid_Serial_Data_Received: start-on-event=DemSatellite_Invalid_OsApplicationInternalBehavior/GetEventFailed, operation=EvtInfo_VDC2_message_LongitudinalAcceleration_Invalid_Serial_Data_Received.GetEventFailed
        OpEventGetEventFailed_GetEventFailed_Event_VDC2_message_LongitudinalAcceleration_Invalid_Serial_Data_Received: start-on-event=DemSatellite_Invalid_OsApplicationInternalBehavior/GetEventFailed, operation=Event_VDC2_message_LongitudinalAcceleration_Invalid_Serial_Data_Received.GetEventFailed
        OpEventGetEventFailed_GetEventFailed_EvtInfo_Radar_MMIC_RFBIST_Component_Internal_Failure: start-on-event=DemSatellite_Invalid_OsApplicationInternalBehavior/GetEventFailed, operation=EvtInfo_Radar_MMIC_RFBIST_Component_Internal_Failure.GetEventFailed
        OpEventGetEventFailed_GetEventFailed_Event_Radar_MMIC_RFBIST_Component_Internal_Failure: start-on-event=DemSatellite_Invalid_OsApplicationInternalBehavior/GetEventFailed, operation=Event_Radar_MMIC_RFBIST_Component_Internal_Failure.GetEventFailed
        OpEventGetEventFailed_GetEventFailed_EvtInfo_Radar_Initial_Alignment_Missing_Calibration: start-on-event=DemSatellite_Invalid_OsApplicationInternalBehavior/GetEventFailed, operation=EvtInfo_Radar_Initial_Alignment_Missing_Calibration.GetEventFailed
        OpEventGetEventFailed_GetEventFailed_Event_Radar_Initial_Alignment_Missing_Calibration: start-on-event=DemSatellite_Invalid_OsApplicationInternalBehavior/GetEventFailed, operation=Event_Radar_Initial_Alignment_Missing_Calibration.GetEventFailed
        OpEventGetEventFailed_GetEventFailed_EvtInfo_Cluster_ECU_OEL_message_Missing_Message: start-on-event=DemSatellite_Invalid_OsApplicationInternalBehavior/GetEventFailed, operation=EvtInfo_Cluster_ECU_OEL_message_Missing_Message.GetEventFailed
        OpEventGetEventFailed_GetEventFailed_Event_Cluster_ECU_OEL_message_Missing_Message: start-on-event=DemSatellite_Invalid_OsApplicationInternalBehavior/GetEventFailed, operation=Event_Cluster_ECU_OEL_message_Missing_Message.GetEventFailed
        OpEventGetEventFailed_GetEventFailed_EvtInfo_AT_AMT_ECU_ETC2_03_message_Missing_Message: start-on-event=DemSatellite_Invalid_OsApplicationInternalBehavior/GetEventFailed, operation=EvtInfo_AT_AMT_ECU_ETC2_03_message_Missing_Message.GetEventFailed
        OpEventGetEventFailed_GetEventFailed_Event_AT_AMT_ECU_ETC2_03_message_Missing_Message: start-on-event=DemSatellite_Invalid_OsApplicationInternalBehavior/GetEventFailed, operation=Event_AT_AMT_ECU_ETC2_03_message_Missing_Message.GetEventFailed
        OpEventGetEventFailed_GetEventFailed_EvtInfo_ADAS_FN_STS_message_MOIS_FN_Switch_STS_Invalid_Serial_Data_Received: start-on-event=DemSatellite_Invalid_OsApplicationInternalBehavior/GetEventFailed, operation=EvtInfo_ADAS_FN_STS_message_MOIS_FN_Switch_STS_Invalid_Serial_Data_Received.GetEventFailed
        OpEventGetEventFailed_GetEventFailed_Event_ADAS_FN_STS_message_MOIS_FN_Switch_STS_Invalid_Serial_Data_Received: start-on-event=DemSatellite_Invalid_OsApplicationInternalBehavior/GetEventFailed, operation=Event_ADAS_FN_STS_message_MOIS_FN_Switch_STS_Invalid_Serial_Data_Received.GetEventFailed
        OpEventGetEventFailed_GetEventFailed_EvtInfo_Radar_Module_Over_Temperature: start-on-event=DemSatellite_Invalid_OsApplicationInternalBehavior/GetEventFailed, operation=EvtInfo_Radar_Module_Over_Temperature.GetEventFailed
        OpEventGetEventFailed_GetEventFailed_Event_Radar_Module_Over_Temperature: start-on-event=DemSatellite_Invalid_OsApplicationInternalBehavior/GetEventFailed, operation=Event_Radar_Module_Over_Temperature.GetEventFailed
        OpEventGetEventFailed_GetEventFailed_EvtInfo_PCAN_TimeSync_Missing_Message: start-on-event=DemSatellite_Invalid_OsApplicationInternalBehavior/GetEventFailed, operation=EvtInfo_PCAN_TimeSync_Missing_Message.GetEventFailed
        OpEventGetEventFailed_GetEventFailed_Event_PCAN_TimeSync_Missing_Message: start-on-event=DemSatellite_Invalid_OsApplicationInternalBehavior/GetEventFailed, operation=Event_PCAN_TimeSync_Missing_Message.GetEventFailed
        OpEventGetEventFailed_GetEventFailed_EvtInfo_Radar_Module_Watchdog_Failure: start-on-event=DemSatellite_Invalid_OsApplicationInternalBehavior/GetEventFailed, operation=EvtInfo_Radar_Module_Watchdog_Failure.GetEventFailed
        OpEventGetEventFailed_GetEventFailed_Event_Radar_Module_Watchdog_Failure: start-on-event=DemSatellite_Invalid_OsApplicationInternalBehavior/GetEventFailed, operation=Event_Radar_Module_Watchdog_Failure.GetEventFailed
        OpEventGetEventFailed_GetEventFailed_EvtInfo_SAS_ECU_SAS_message_Missing_Message: start-on-event=DemSatellite_Invalid_OsApplicationInternalBehavior/GetEventFailed, operation=EvtInfo_SAS_ECU_SAS_message_Missing_Message.GetEventFailed
        OpEventGetEventFailed_GetEventFailed_Event_SAS_ECU_SAS_message_Missing_Message: start-on-event=DemSatellite_Invalid_OsApplicationInternalBehavior/GetEventFailed, operation=Event_SAS_ECU_SAS_message_Missing_Message.GetEventFailed
        OpEventGetEventFailed_GetEventFailed_EvtInfo_ECU_NVM_Corruption_Program_memory_Failure: start-on-event=DemSatellite_Invalid_OsApplicationInternalBehavior/GetEventFailed, operation=EvtInfo_ECU_NVM_Corruption_Program_memory_Failure.GetEventFailed
        OpEventGetEventFailed_GetEventFailed_Event_ECU_NVM_Corruption_Program_memory_Failure: start-on-event=DemSatellite_Invalid_OsApplicationInternalBehavior/GetEventFailed, operation=Event_ECU_NVM_Corruption_Program_memory_Failure.GetEventFailed
        OpEventGetEventFailed_GetEventFailed_EvtInfo_Cluster_ECU_TD_message_Missing_Message: start-on-event=DemSatellite_Invalid_OsApplicationInternalBehavior/GetEventFailed, operation=EvtInfo_Cluster_ECU_TD_message_Missing_Message.GetEventFailed
        OpEventGetEventFailed_GetEventFailed_Event_Cluster_ECU_TD_message_Missing_Message: start-on-event=DemSatellite_Invalid_OsApplicationInternalBehavior/GetEventFailed, operation=Event_Cluster_ECU_TD_message_Missing_Message.GetEventFailed
        OpEventGetEventFailed_GetEventFailed_EvtInfo_PCAN_Communication_Bus_Off: start-on-event=DemSatellite_Invalid_OsApplicationInternalBehavior/GetEventFailed, operation=EvtInfo_PCAN_Communication_Bus_Off.GetEventFailed
        OpEventGetEventFailed_GetEventFailed_Event_PCAN_Communication_Bus_Off: start-on-event=DemSatellite_Invalid_OsApplicationInternalBehavior/GetEventFailed, operation=Event_PCAN_Communication_Bus_Off.GetEventFailed
        OpEventGetEventFailed_GetEventFailed_EvtInfo_Front_Left_Side_Radar_Missing_Message: start-on-event=DemSatellite_Invalid_OsApplicationInternalBehavior/GetEventFailed, operation=EvtInfo_Front_Left_Side_Radar_Missing_Message.GetEventFailed
        OpEventGetEventFailed_GetEventFailed_Event_Front_Left_Side_Radar_Missing_Message: start-on-event=DemSatellite_Invalid_OsApplicationInternalBehavior/GetEventFailed, operation=Event_Front_Left_Side_Radar_Missing_Message.GetEventFailed
        OpEventGetEventFailed_GetEventFailed_EvtInfo_Manual_ETC2_message_Transcurrent_gear_Invalid_Serial_Data_Received: start-on-event=DemSatellite_Invalid_OsApplicationInternalBehavior/GetEventFailed, operation=EvtInfo_Manual_ETC2_message_Transcurrent_gear_Invalid_Serial_Data_Received.GetEventFailed
        OpEventGetEventFailed_GetEventFailed_Event_Manual_ETC2_message_Transcurrent_gear_Invalid_Serial_Data_Received: start-on-event=DemSatellite_Invalid_OsApplicationInternalBehavior/GetEventFailed, operation=Event_Manual_ETC2_message_Transcurrent_gear_Invalid_Serial_Data_Received.GetEventFailed
        OpEventGetEventFailed_GetEventFailed_EvtInfo_SAS_ECU_erratic_communication_Erratic: start-on-event=DemSatellite_Invalid_OsApplicationInternalBehavior/GetEventFailed, operation=EvtInfo_SAS_ECU_erratic_communication_Erratic.GetEventFailed
        OpEventGetEventFailed_GetEventFailed_Event_SAS_ECU_erratic_communication_Erratic: start-on-event=DemSatellite_Invalid_OsApplicationInternalBehavior/GetEventFailed, operation=Event_SAS_ECU_erratic_communication_Erratic.GetEventFailed
        OpEventGetEventFailed_GetEventFailed_EvtInfo_VDC2_message_Yaw_rate_Invalid_Serial_Data_Received: start-on-event=DemSatellite_Invalid_OsApplicationInternalBehavior/GetEventFailed, operation=EvtInfo_VDC2_message_Yaw_rate_Invalid_Serial_Data_Received.GetEventFailed
        OpEventGetEventFailed_GetEventFailed_Event_VDC2_message_Yaw_rate_Invalid_Serial_Data_Received: start-on-event=DemSatellite_Invalid_OsApplicationInternalBehavior/GetEventFailed, operation=Event_VDC2_message_Yaw_rate_Invalid_Serial_Data_Received.GetEventFailed
        OpEventGetEventFailed_GetEventFailed_EvtInfo_Cluster_ECU_TD_erratic_communication_Erratic: start-on-event=DemSatellite_Invalid_OsApplicationInternalBehavior/GetEventFailed, operation=EvtInfo_Cluster_ECU_TD_erratic_communication_Erratic.GetEventFailed
        OpEventGetEventFailed_GetEventFailed_Event_Cluster_ECU_TD_erratic_communication_Erratic: start-on-event=DemSatellite_Invalid_OsApplicationInternalBehavior/GetEventFailed, operation=Event_Cluster_ECU_TD_erratic_communication_Erratic.GetEventFailed
        OpEventGetEventFailed_GetEventFailed_EvtInfo_EMS_ECU_CCVS1_message_Missing_Message: start-on-event=DemSatellite_Invalid_OsApplicationInternalBehavior/GetEventFailed, operation=EvtInfo_EMS_ECU_CCVS1_message_Missing_Message.GetEventFailed
        OpEventGetEventFailed_GetEventFailed_Event_EMS_ECU_CCVS1_message_Missing_Message: start-on-event=DemSatellite_Invalid_OsApplicationInternalBehavior/GetEventFailed, operation=Event_EMS_ECU_CCVS1_message_Missing_Message.GetEventFailed
        OpEventGetEventFailed_GetEventFailed_EvtInfo_Radar_Mounting_Orientation_Incorrect_Assembly: start-on-event=DemSatellite_Invalid_OsApplicationInternalBehavior/GetEventFailed, operation=EvtInfo_Radar_Mounting_Orientation_Incorrect_Assembly.GetEventFailed
        OpEventGetEventFailed_GetEventFailed_Event_Radar_Mounting_Orientation_Incorrect_Assembly: start-on-event=DemSatellite_Invalid_OsApplicationInternalBehavior/GetEventFailed, operation=Event_Radar_Mounting_Orientation_Incorrect_Assembly.GetEventFailed
        OpEventGetEventFailed_GetEventFailed_EvtInfo_EMS_ECU_ETC2_erratic_communication_Erractic: start-on-event=DemSatellite_Invalid_OsApplicationInternalBehavior/GetEventFailed, operation=EvtInfo_EMS_ECU_ETC2_erratic_communication_Erractic.GetEventFailed
        OpEventGetEventFailed_GetEventFailed_Event_EMS_ECU_ETC2_erratic_communication_Erractic: start-on-event=DemSatellite_Invalid_OsApplicationInternalBehavior/GetEventFailed, operation=Event_EMS_ECU_ETC2_erratic_communication_Erractic.GetEventFailed
        OpEventGetEventFailed_GetEventFailed_EvtInfo_Cluster_ECU_ADAS_FN_STS_erratic_communication_Erratic: start-on-event=DemSatellite_Invalid_OsApplicationInternalBehavior/GetEventFailed, operation=EvtInfo_Cluster_ECU_ADAS_FN_STS_erratic_communication_Erratic.GetEventFailed
        OpEventGetEventFailed_GetEventFailed_Event_Cluster_ECU_ADAS_FN_STS_erratic_communication_Erratic: start-on-event=DemSatellite_Invalid_OsApplicationInternalBehavior/GetEventFailed, operation=Event_Cluster_ECU_ADAS_FN_STS_erratic_communication_Erratic.GetEventFailed
        OpEventGetEventFailed_GetEventFailed_EvtInfo_ESC_ECU_VDC2_message_Missing_Message: start-on-event=DemSatellite_Invalid_OsApplicationInternalBehavior/GetEventFailed, operation=EvtInfo_ESC_ECU_VDC2_message_Missing_Message.GetEventFailed
        OpEventGetEventFailed_GetEventFailed_Event_ESC_ECU_VDC2_message_Missing_Message: start-on-event=DemSatellite_Invalid_OsApplicationInternalBehavior/GetEventFailed, operation=Event_ESC_ECU_VDC2_message_Missing_Message.GetEventFailed
        OpEventGetEventFailed_GetEventFailed_EvtInfo_CLS_TX_16_message_Transmission_Type_info_Invalid_Serial_Data_Received: start-on-event=DemSatellite_Invalid_OsApplicationInternalBehavior/GetEventFailed, operation=EvtInfo_CLS_TX_16_message_Transmission_Type_info_Invalid_Serial_Data_Received.GetEventFailed
        OpEventGetEventFailed_GetEventFailed_Event_CLS_TX_16_message_Transmission_Type_info_Invalid_Serial_Data_Received: start-on-event=DemSatellite_Invalid_OsApplicationInternalBehavior/GetEventFailed, operation=Event_CLS_TX_16_message_Transmission_Type_info_Invalid_Serial_Data_Received.GetEventFailed
        OpEventGetEventFailed_GetEventFailed_EvtInfo_Cluster_ECU_CLS_Tx_4_erratic_communication_Erratic: start-on-event=DemSatellite_Invalid_OsApplicationInternalBehavior/GetEventFailed, operation=EvtInfo_Cluster_ECU_CLS_Tx_4_erratic_communication_Erratic.GetEventFailed
        OpEventGetEventFailed_GetEventFailed_Event_Cluster_ECU_CLS_Tx_4_erratic_communication_Erratic: start-on-event=DemSatellite_Invalid_OsApplicationInternalBehavior/GetEventFailed, operation=Event_Cluster_ECU_CLS_Tx_4_erratic_communication_Erratic.GetEventFailed
        OpEventGetEventFailed_GetEventFailed_EvtInfo_Cluster_ECU_ADAS_FN_STS_message_Missing_Message: start-on-event=DemSatellite_Invalid_OsApplicationInternalBehavior/GetEventFailed, operation=EvtInfo_Cluster_ECU_ADAS_FN_STS_message_Missing_Message.GetEventFailed
        OpEventGetEventFailed_GetEventFailed_Event_Cluster_ECU_ADAS_FN_STS_message_Missing_Message: start-on-event=DemSatellite_Invalid_OsApplicationInternalBehavior/GetEventFailed, operation=Event_Cluster_ECU_ADAS_FN_STS_message_Missing_Message.GetEventFailed
        OpEventGetEventFailed_GetEventFailed_EvtInfo_Vehicle_Dataset_value_of_signal_protection_calculation_Incorrect: start-on-event=DemSatellite_Invalid_OsApplicationInternalBehavior/GetEventFailed, operation=EvtInfo_Vehicle_Dataset_value_of_signal_protection_calculation_Incorrect.GetEventFailed
        OpEventGetEventFailed_GetEventFailed_Event_Vehicle_Dataset_value_of_signal_protection_calculation_Incorrect: start-on-event=DemSatellite_Invalid_OsApplicationInternalBehavior/GetEventFailed, operation=Event_Vehicle_Dataset_value_of_signal_protection_calculation_Incorrect.GetEventFailed
        OpEventGetEventFailed_GetEventFailed_EvtInfo_Cluster_ECU_CLS_Tx_16_erratic_communication_Erratic: start-on-event=DemSatellite_Invalid_OsApplicationInternalBehavior/GetEventFailed, operation=EvtInfo_Cluster_ECU_CLS_Tx_16_erratic_communication_Erratic.GetEventFailed
        OpEventGetEventFailed_GetEventFailed_Event_Cluster_ECU_CLS_Tx_16_erratic_communication_Erratic: start-on-event=DemSatellite_Invalid_OsApplicationInternalBehavior/GetEventFailed, operation=Event_Cluster_ECU_CLS_Tx_16_erratic_communication_Erratic.GetEventFailed
        OpEventGetEventFailed_GetEventFailed_EvtInfo_Cluster_ECU_OEL_erratic_communication_Erratic: start-on-event=DemSatellite_Invalid_OsApplicationInternalBehavior/GetEventFailed, operation=EvtInfo_Cluster_ECU_OEL_erratic_communication_Erratic.GetEventFailed
        OpEventGetEventFailed_GetEventFailed_Event_Cluster_ECU_OEL_erratic_communication_Erratic: start-on-event=DemSatellite_Invalid_OsApplicationInternalBehavior/GetEventFailed, operation=Event_Cluster_ECU_OEL_erratic_communication_Erratic.GetEventFailed
        OpEventGetEventFailed_GetEventFailed_EvtInfo_Cluster_ECU_CLS_Tx_4_message_Missing_Message: start-on-event=DemSatellite_Invalid_OsApplicationInternalBehavior/GetEventFailed, operation=EvtInfo_Cluster_ECU_CLS_Tx_4_message_Missing_Message.GetEventFailed
        OpEventGetEventFailed_GetEventFailed_Event_Cluster_ECU_CLS_Tx_4_message_Missing_Message: start-on-event=DemSatellite_Invalid_OsApplicationInternalBehavior/GetEventFailed, operation=Event_Cluster_ECU_CLS_Tx_4_message_Missing_Message.GetEventFailed
        OpEventGetEventFailed_GetEventFailed_EvtInfo_Radar_Performance_Capability_Algorithm_Based_Failure: start-on-event=DemSatellite_Invalid_OsApplicationInternalBehavior/GetEventFailed, operation=EvtInfo_Radar_Performance_Capability_Algorithm_Based_Failure.GetEventFailed
        OpEventGetEventFailed_GetEventFailed_Event_Radar_Performance_Capability_Algorithm_Based_Failure: start-on-event=DemSatellite_Invalid_OsApplicationInternalBehavior/GetEventFailed, operation=Event_Radar_Performance_Capability_Algorithm_Based_Failure.GetEventFailed
        OpEventGetEventFailed_GetEventFailed_EvtInfo_Radar_AutoAlignment_Range_Alignment_or_Adjustement_Incorrect: start-on-event=DemSatellite_Invalid_OsApplicationInternalBehavior/GetEventFailed, operation=EvtInfo_Radar_AutoAlignment_Range_Alignment_or_Adjustement_Incorrect.GetEventFailed
        OpEventGetEventFailed_GetEventFailed_Event_Radar_AutoAlignment_Range_Alignment_or_Adjustement_Incorrect: start-on-event=DemSatellite_Invalid_OsApplicationInternalBehavior/GetEventFailed, operation=Event_Radar_AutoAlignment_Range_Alignment_or_Adjustement_Incorrect.GetEventFailed
        OpEventGetEventFailed_GetEventFailed_EvtInfo_EMS_ECU_CCVS1_erratic_communication_Erractic: start-on-event=DemSatellite_Invalid_OsApplicationInternalBehavior/GetEventFailed, operation=EvtInfo_EMS_ECU_CCVS1_erratic_communication_Erractic.GetEventFailed
        OpEventGetEventFailed_GetEventFailed_Event_EMS_ECU_CCVS1_erratic_communication_Erractic: start-on-event=DemSatellite_Invalid_OsApplicationInternalBehavior/GetEventFailed, operation=Event_EMS_ECU_CCVS1_erratic_communication_Erractic.GetEventFailed
        OpEventGetEventFailed_GetEventFailed_EvtInfo_Radar_System_Battery_Low_Voltage_System_Voltage_Low: start-on-event=DemSatellite_Invalid_OsApplicationInternalBehavior/GetEventFailed, operation=EvtInfo_Radar_System_Battery_Low_Voltage_System_Voltage_Low.GetEventFailed
        OpEventGetEventFailed_GetEventFailed_Event_Radar_System_Battery_Low_Voltage_System_Voltage_Low: start-on-event=DemSatellite_Invalid_OsApplicationInternalBehavior/GetEventFailed, operation=Event_Radar_System_Battery_Low_Voltage_System_Voltage_Low.GetEventFailed
        OpEventGetEventFailed_GetEventFailed_EvtInfo_Radar_SMC_General_Checksum_Failure: start-on-event=DemSatellite_Invalid_OsApplicationInternalBehavior/GetEventFailed, operation=EvtInfo_Radar_SMC_General_Checksum_Failure.GetEventFailed
        OpEventGetEventFailed_GetEventFailed_Event_Radar_SMC_General_Checksum_Failure: start-on-event=DemSatellite_Invalid_OsApplicationInternalBehavior/GetEventFailed, operation=Event_Radar_SMC_General_Checksum_Failure.GetEventFailed
        OpEventGetEventFailed_GetEventFailed_EvtInfo_Radar_Pin_Position_Wrong_Mounting_Position: start-on-event=DemSatellite_Invalid_OsApplicationInternalBehavior/GetEventFailed, operation=EvtInfo_Radar_Pin_Position_Wrong_Mounting_Position.GetEventFailed
        OpEventGetEventFailed_GetEventFailed_Event_Radar_Pin_Position_Wrong_Mounting_Position: start-on-event=DemSatellite_Invalid_OsApplicationInternalBehavior/GetEventFailed, operation=Event_Radar_Pin_Position_Wrong_Mounting_Position.GetEventFailed
        OpEventGetEventFailed_GetEventFailed_EvtInfo_VDC2_message_Lateral_Accleration_Invalid_Serial_Data_Received: start-on-event=DemSatellite_Invalid_OsApplicationInternalBehavior/GetEventFailed, operation=EvtInfo_VDC2_message_Lateral_Accleration_Invalid_Serial_Data_Received.GetEventFailed
        OpEventGetEventFailed_GetEventFailed_Event_VDC2_message_Lateral_Accleration_Invalid_Serial_Data_Received: start-on-event=DemSatellite_Invalid_OsApplicationInternalBehavior/GetEventFailed, operation=Event_VDC2_message_Lateral_Accleration_Invalid_Serial_Data_Received.GetEventFailed
        OpEventGetEventFailed_GetEventFailed_EvtInfo_ADAS_FN_STS_message_BSIS_FN_Switch_STS_Invalid_Serial_Data_Received: start-on-event=DemSatellite_Invalid_OsApplicationInternalBehavior/GetEventFailed, operation=EvtInfo_ADAS_FN_STS_message_BSIS_FN_Switch_STS_Invalid_Serial_Data_Received.GetEventFailed
        OpEventGetEventFailed_GetEventFailed_Event_ADAS_FN_STS_message_BSIS_FN_Switch_STS_Invalid_Serial_Data_Received: start-on-event=DemSatellite_Invalid_OsApplicationInternalBehavior/GetEventFailed, operation=Event_ADAS_FN_STS_message_BSIS_FN_Switch_STS_Invalid_Serial_Data_Received.GetEventFailed
        OpEventGetEventFailed_GetEventFailed_EvtInfo_Radar_AutoAlignment_Misalignment_Performance_or_Incorrect_Operation: start-on-event=DemSatellite_Invalid_OsApplicationInternalBehavior/GetEventFailed, operation=EvtInfo_Radar_AutoAlignment_Misalignment_Performance_or_Incorrect_Operation.GetEventFailed
        OpEventGetEventFailed_GetEventFailed_Event_Radar_AutoAlignment_Misalignment_Performance_or_Incorrect_Operation: start-on-event=DemSatellite_Invalid_OsApplicationInternalBehavior/GetEventFailed, operation=Event_Radar_AutoAlignment_Misalignment_Performance_or_Incorrect_Operation.GetEventFailed
        OpEventGetEventFailed_GetEventFailed_EvtInfo_ESC_ECU_VDC2_erratic_communication_Erratic: start-on-event=DemSatellite_Invalid_OsApplicationInternalBehavior/GetEventFailed, operation=EvtInfo_ESC_ECU_VDC2_erratic_communication_Erratic.GetEventFailed
        OpEventGetEventFailed_GetEventFailed_Event_ESC_ECU_VDC2_erratic_communication_Erratic: start-on-event=DemSatellite_Invalid_OsApplicationInternalBehavior/GetEventFailed, operation=Event_ESC_ECU_VDC2_erratic_communication_Erratic.GetEventFailed
        OpEventGetEventFailed_GetEventFailed_EvtInfo_Application_Interface_Lookup_Performance_or_Incorrect_Operation: start-on-event=DemSatellite_Invalid_OsApplicationInternalBehavior/GetEventFailed, operation=EvtInfo_Application_Interface_Lookup_Performance_or_Incorrect_Operation.GetEventFailed
        OpEventGetEventFailed_GetEventFailed_Event_Application_Interface_Lookup_Performance_or_Incorrect_Operation: start-on-event=DemSatellite_Invalid_OsApplicationInternalBehavior/GetEventFailed, operation=Event_Application_Interface_Lookup_Performance_or_Incorrect_Operation.GetEventFailed
        OpEventGetEventFailed_GetEventFailed_EvtInfo_EMS_ECU_VD_message_Missing_Message: start-on-event=DemSatellite_Invalid_OsApplicationInternalBehavior/GetEventFailed, operation=EvtInfo_EMS_ECU_VD_message_Missing_Message.GetEventFailed
        OpEventGetEventFailed_GetEventFailed_Event_EMS_ECU_VD_message_Missing_Message: start-on-event=DemSatellite_Invalid_OsApplicationInternalBehavior/GetEventFailed, operation=Event_EMS_ECU_VD_message_Missing_Message.GetEventFailed
        OpEventGetEventFailed_GetEventFailed_EvtInfo_Radar_Platform_Time_System_Programming_Failure: start-on-event=DemSatellite_Invalid_OsApplicationInternalBehavior/GetEventFailed, operation=EvtInfo_Radar_Platform_Time_System_Programming_Failure.GetEventFailed
        OpEventGetEventFailed_GetEventFailed_Event_Radar_Platform_Time_System_Programming_Failure: start-on-event=DemSatellite_Invalid_OsApplicationInternalBehavior/GetEventFailed, operation=Event_Radar_Platform_Time_System_Programming_Failure.GetEventFailed
        OpEventGetEventFailed_GetEventFailed_EvtInfo_OEL_message_Turn_Signal_Switch_Invalid_Serial_Data_Received: start-on-event=DemSatellite_Invalid_OsApplicationInternalBehavior/GetEventFailed, operation=EvtInfo_OEL_message_Turn_Signal_Switch_Invalid_Serial_Data_Received.GetEventFailed
        OpEventGetEventFailed_GetEventFailed_Event_OEL_message_Turn_Signal_Switch_Invalid_Serial_Data_Received: start-on-event=DemSatellite_Invalid_OsApplicationInternalBehavior/GetEventFailed, operation=Event_OEL_message_Turn_Signal_Switch_Invalid_Serial_Data_Received.GetEventFailed
        OpEventGetEventFailed_GetEventFailed_EvtInfo_Radar_calibration_Calibration_or_Paramater_Memory_Failure: start-on-event=DemSatellite_Invalid_OsApplicationInternalBehavior/GetEventFailed, operation=EvtInfo_Radar_calibration_Calibration_or_Paramater_Memory_Failure.GetEventFailed
        OpEventGetEventFailed_GetEventFailed_Event_Radar_calibration_Calibration_or_Paramater_Memory_Failure: start-on-event=DemSatellite_Invalid_OsApplicationInternalBehavior/GetEventFailed, operation=Event_Radar_calibration_Calibration_or_Paramater_Memory_Failure.GetEventFailed
        OpEventGetEventFailed_GetEventFailed_GeneralEvtInfo: start-on-event=DemSatellite_Invalid_OsApplicationInternalBehavior/GetEventFailed, operation=GeneralEvtInfo.GetEventFailed
        OpEventGetEventTested_GetEventTested_EvtInfo_SAS_message_Steering_Wheel_Angle_Invalid_Serial_Data_Received: start-on-event=DemSatellite_Invalid_OsApplicationInternalBehavior/GetEventTested, operation=EvtInfo_SAS_message_Steering_Wheel_Angle_Invalid_Serial_Data_Received.GetEventTested
        OpEventGetEventTested_GetEventTested_Event_SAS_message_Steering_Wheel_Angle_Invalid_Serial_Data_Received: start-on-event=DemSatellite_Invalid_OsApplicationInternalBehavior/GetEventTested, operation=Event_SAS_message_Steering_Wheel_Angle_Invalid_Serial_Data_Received.GetEventTested
        OpEventGetEventTested_GetEventTested_EvtInfo_AT_AMT_ETC2_message_Transcurrent_gear_Invalid_Serial_Data_Received: start-on-event=DemSatellite_Invalid_OsApplicationInternalBehavior/GetEventTested, operation=EvtInfo_AT_AMT_ETC2_message_Transcurrent_gear_Invalid_Serial_Data_Received.GetEventTested
        OpEventGetEventTested_GetEventTested_Event_AT_AMT_ETC2_message_Transcurrent_gear_Invalid_Serial_Data_Received: start-on-event=DemSatellite_Invalid_OsApplicationInternalBehavior/GetEventTested, operation=Event_AT_AMT_ETC2_message_Transcurrent_gear_Invalid_Serial_Data_Received.GetEventTested
        OpEventGetEventTested_GetEventTested_EvtInfo_Radar_AutoAlignment_Algorithm_Signal_Calculation_Failure: start-on-event=DemSatellite_Invalid_OsApplicationInternalBehavior/GetEventTested, operation=EvtInfo_Radar_AutoAlignment_Algorithm_Signal_Calculation_Failure.GetEventTested
        OpEventGetEventTested_GetEventTested_Event_Radar_AutoAlignment_Algorithm_Signal_Calculation_Failure: start-on-event=DemSatellite_Invalid_OsApplicationInternalBehavior/GetEventTested, operation=Event_Radar_AutoAlignment_Algorithm_Signal_Calculation_Failure.GetEventTested
        OpEventGetEventTested_GetEventTested_EvtInfo_Vehicle_DataSet_Not_Configured: start-on-event=DemSatellite_Invalid_OsApplicationInternalBehavior/GetEventTested, operation=EvtInfo_Vehicle_DataSet_Not_Configured.GetEventTested
        OpEventGetEventTested_GetEventTested_Event_Vehicle_DataSet_Not_Configured: start-on-event=DemSatellite_Invalid_OsApplicationInternalBehavior/GetEventTested, operation=Event_Vehicle_DataSet_Not_Configured.GetEventTested
        OpEventGetEventTested_GetEventTested_EvtInfo_Radar_Module_System_Internal_Failure: start-on-event=DemSatellite_Invalid_OsApplicationInternalBehavior/GetEventTested, operation=EvtInfo_Radar_Module_System_Internal_Failure.GetEventTested
        OpEventGetEventTested_GetEventTested_Event_Radar_Module_System_Internal_Failure: start-on-event=DemSatellite_Invalid_OsApplicationInternalBehavior/GetEventTested, operation=Event_Radar_Module_System_Internal_Failure.GetEventTested
        OpEventGetEventTested_GetEventTested_EvtInfo_Radar_MMIC_Component_Failure: start-on-event=DemSatellite_Invalid_OsApplicationInternalBehavior/GetEventTested, operation=EvtInfo_Radar_MMIC_Component_Failure.GetEventTested
        OpEventGetEventTested_GetEventTested_Event_Radar_MMIC_Component_Failure: start-on-event=DemSatellite_Invalid_OsApplicationInternalBehavior/GetEventTested, operation=Event_Radar_MMIC_Component_Failure.GetEventTested
        OpEventGetEventTested_GetEventTested_EvtInfo_Radar_Module_General_Memory_Failure: start-on-event=DemSatellite_Invalid_OsApplicationInternalBehavior/GetEventTested, operation=EvtInfo_Radar_Module_General_Memory_Failure.GetEventTested
        OpEventGetEventTested_GetEventTested_Event_Radar_Module_General_Memory_Failure: start-on-event=DemSatellite_Invalid_OsApplicationInternalBehavior/GetEventTested, operation=Event_Radar_Module_General_Memory_Failure.GetEventTested
        OpEventGetEventTested_GetEventTested_EvtInfo_Radar_System_Battery_High_Voltage_System_Voltage_High: start-on-event=DemSatellite_Invalid_OsApplicationInternalBehavior/GetEventTested, operation=EvtInfo_Radar_System_Battery_High_Voltage_System_Voltage_High.GetEventTested
        OpEventGetEventTested_GetEventTested_Event_Radar_System_Battery_High_Voltage_System_Voltage_High: start-on-event=DemSatellite_Invalid_OsApplicationInternalBehavior/GetEventTested, operation=Event_Radar_System_Battery_High_Voltage_System_Voltage_High.GetEventTested
        OpEventGetEventTested_GetEventTested_EvtInfo_CCVS1_message_Vehicle_Speed_Invalid_Serial_Data_Received: start-on-event=DemSatellite_Invalid_OsApplicationInternalBehavior/GetEventTested, operation=EvtInfo_CCVS1_message_Vehicle_Speed_Invalid_Serial_Data_Received.GetEventTested
        OpEventGetEventTested_GetEventTested_Event_CCVS1_message_Vehicle_Speed_Invalid_Serial_Data_Received: start-on-event=DemSatellite_Invalid_OsApplicationInternalBehavior/GetEventTested, operation=Event_CCVS1_message_Vehicle_Speed_Invalid_Serial_Data_Received.GetEventTested
        OpEventGetEventTested_GetEventTested_EvtInfo_EMS_ECU_VD_erratic_communication_Erratic: start-on-event=DemSatellite_Invalid_OsApplicationInternalBehavior/GetEventTested, operation=EvtInfo_EMS_ECU_VD_erratic_communication_Erratic.GetEventTested
        OpEventGetEventTested_GetEventTested_Event_EMS_ECU_VD_erratic_communication_Erratic: start-on-event=DemSatellite_Invalid_OsApplicationInternalBehavior/GetEventTested, operation=Event_EMS_ECU_VD_erratic_communication_Erratic.GetEventTested
        OpEventGetEventTested_GetEventTested_EvtInfo_EMS_ECU_ETC2_00_message_Missing_Message: start-on-event=DemSatellite_Invalid_OsApplicationInternalBehavior/GetEventTested, operation=EvtInfo_EMS_ECU_ETC2_00_message_Missing_Message.GetEventTested
        OpEventGetEventTested_GetEventTested_Event_EMS_ECU_ETC2_00_message_Missing_Message: start-on-event=DemSatellite_Invalid_OsApplicationInternalBehavior/GetEventTested, operation=Event_EMS_ECU_ETC2_00_message_Missing_Message.GetEventTested
        OpEventGetEventTested_GetEventTested_EvtInfo_Cluster_ECU_CLS_Tx_16_message_Missing_Message: start-on-event=DemSatellite_Invalid_OsApplicationInternalBehavior/GetEventTested, operation=EvtInfo_Cluster_ECU_CLS_Tx_16_message_Missing_Message.GetEventTested
        OpEventGetEventTested_GetEventTested_Event_Cluster_ECU_CLS_Tx_16_message_Missing_Message: start-on-event=DemSatellite_Invalid_OsApplicationInternalBehavior/GetEventTested, operation=Event_Cluster_ECU_CLS_Tx_16_message_Missing_Message.GetEventTested
        OpEventGetEventTested_GetEventTested_EvtInfo_Exceeded_Security_Access_0x27_Attempt_Threshold_Authentication_Failure: start-on-event=DemSatellite_Invalid_OsApplicationInternalBehavior/GetEventTested, operation=EvtInfo_Exceeded_Security_Access_0x27_Attempt_Threshold_Authentication_Failure.GetEventTested
        OpEventGetEventTested_GetEventTested_Event_Exceeded_Security_Access_0x27_Attempt_Threshold_Authentication_Failure: start-on-event=DemSatellite_Invalid_OsApplicationInternalBehavior/GetEventTested, operation=Event_Exceeded_Security_Access_0x27_Attempt_Threshold_Authentication_Failure.GetEventTested
        OpEventGetEventTested_GetEventTested_EvtInfo_Front_Left_Side_Radar_value_of_signal_protection_calculation_Incorrect: start-on-event=DemSatellite_Invalid_OsApplicationInternalBehavior/GetEventTested, operation=EvtInfo_Front_Left_Side_Radar_value_of_signal_protection_calculation_Incorrect.GetEventTested
        OpEventGetEventTested_GetEventTested_Event_Front_Left_Side_Radar_value_of_signal_protection_calculation_Incorrect: start-on-event=DemSatellite_Invalid_OsApplicationInternalBehavior/GetEventTested, operation=Event_Front_Left_Side_Radar_value_of_signal_protection_calculation_Incorrect.GetEventTested
        OpEventGetEventTested_GetEventTested_EvtInfo_AT_AMT_ETC2_erratic_communication_Erratic: start-on-event=DemSatellite_Invalid_OsApplicationInternalBehavior/GetEventTested, operation=EvtInfo_AT_AMT_ETC2_erratic_communication_Erratic.GetEventTested
        OpEventGetEventTested_GetEventTested_Event_AT_AMT_ETC2_erratic_communication_Erratic: start-on-event=DemSatellite_Invalid_OsApplicationInternalBehavior/GetEventTested, operation=Event_AT_AMT_ETC2_erratic_communication_Erratic.GetEventTested
        OpEventGetEventTested_GetEventTested_EvtInfo_VCAN_Communication_Bus_Off: start-on-event=DemSatellite_Invalid_OsApplicationInternalBehavior/GetEventTested, operation=EvtInfo_VCAN_Communication_Bus_Off.GetEventTested
        OpEventGetEventTested_GetEventTested_Event_VCAN_Communication_Bus_Off: start-on-event=DemSatellite_Invalid_OsApplicationInternalBehavior/GetEventTested, operation=Event_VCAN_Communication_Bus_Off.GetEventTested
